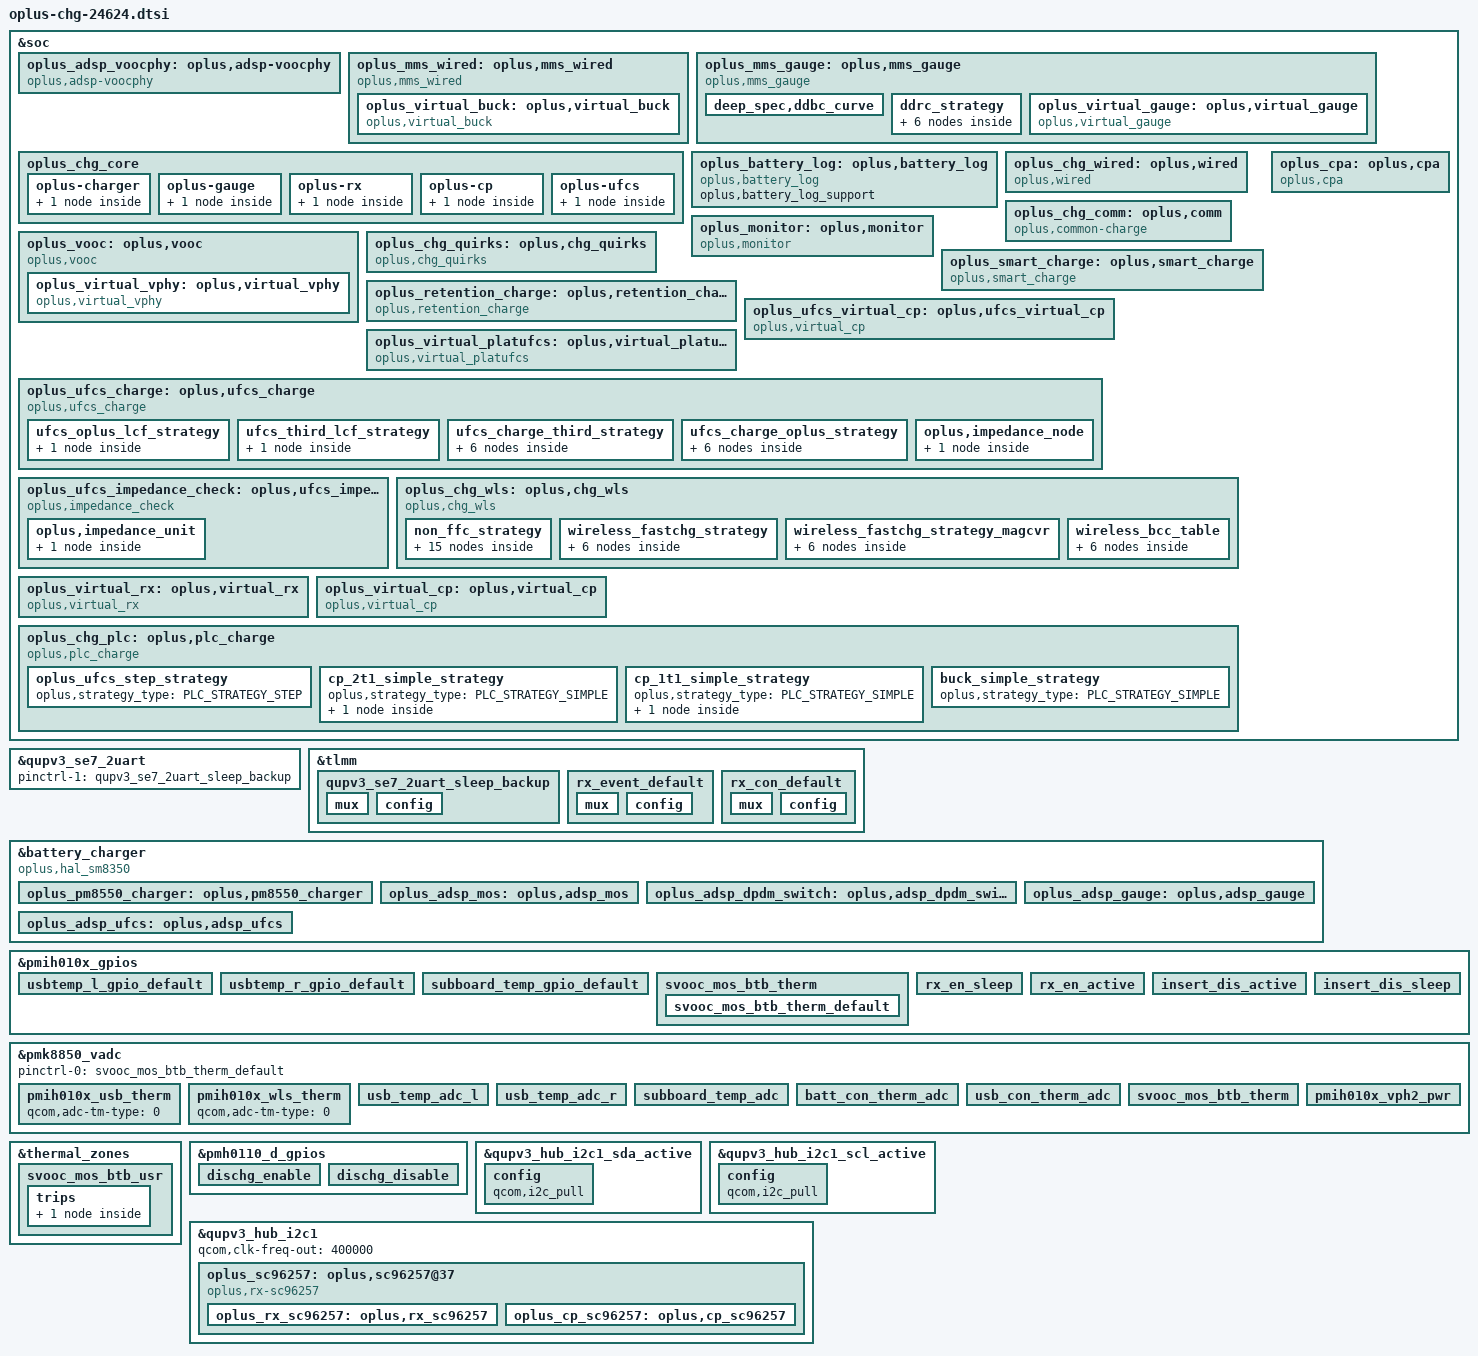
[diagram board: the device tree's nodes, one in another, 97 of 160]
//ifdef OPLUS_FEATURE_CHG_BASIC
//BSP.CHG.Basic, 2023/04/19, sjc Add for charging

#include "oplus-chg-8850.h.dtsi"
#include "oplus-chg-24624-fw.dtsi"

/*
 * NOTICE:
 * sector 1: wired charging
 * sector 2: ufcs
 * sector 3: wls charging
 */

//#ifdef OPLUS_FEATURE_CHG_BASIC /* BSP.CHG.Basic, 2023/04/19, sjc Add for wired charging */
//for wired charging config
&soc {
	oplus_adsp_voocphy: oplus,adsp-voocphy {
		compatible = "oplus,adsp-voocphy";
		oplus,ic_type = <OPLUS_CHG_IC_VPHY>;
		oplus,ic_index = <0>;
		oplus,vooc-version = <VOOC_VERSION_5_0>;

		oplus_spec,vooc_low_temp = <50>;
		oplus_spec,vooc_little_cold_temp = <50>;
		oplus_spec,vooc_cool_temp = <120>;
		oplus_spec,vooc_little_cool_temp = <160>;
		oplus_spec,vooc_little_cool_high_temp = <210>;
		oplus_spec,vooc_normal_low_temp = <350>;
		oplus_spec,vooc_normal_high_temp = <440>;
		oplus_spec,vooc_high_temp = <500>;
		oplus_spec,vooc_over_high_temp = <510>;
		oplus_spec,vooc_low_soc = <0>;
		oplus_spec,vooc_high_soc = <90>;

		oplus_spec,vooc_warm_vol_thr = <4000>;
		oplus_spec,vooc_warm_soc_thr = <55>;
	};

	oplus_mms_wired: oplus,mms_wired {
		compatible = "oplus,mms_wired";
		oplus,buck_ic = <&oplus_virtual_buck>;

		oplus,adc_info_name = "855";

		/* BSP.CHG.Basic, 2024/09/27, Add for:
		High temperature long-term solution for Battery bulge from MTK*/
		high-temp-scheme;

		oplus,support_usbtemp_protect_v2;
		oplus,support_wlsotg_non_coexistence;
		oplus_spec,usbtemp_batt_temp_low = <50>;
		oplus_spec,usbtemp_batt_temp_high = <50>;
		oplus_spec,usbtemp_batt_temp_over_hot = <60>;
		oplus_spec,usbtemp_ntc_temp_low = <57>;
		oplus_spec,usbtemp_ntc_temp_high = <69>;
		oplus_spec,usbtemp_temp_gap_low_with_batt_temp = <7>;
		oplus_spec,usbtemp_temp_gap_with_batt_temp_in_over_hot = <15>;
		oplus_spec,usbtemp_temp_gap_high_with_batt_temp = <12>;
		oplus_spec,usbtemp_temp_gap_low_without_batt_temp = <12>;
		oplus_spec,usbtemp_temp_gap_high_without_batt_temp = <24>;
		oplus_spec,usbtemp_rise_fast_temp_low = <3>;
		oplus_spec,usbtemp_rise_fast_temp_high = <3>;
		oplus_spec,usbtemp_rise_fast_temp_count_low = <30>;
		oplus_spec,usbtemp_rise_fast_temp_count_high = <20>;
		oplus_spec,usbtemp_cool_down_ntc_low = <54>;
		oplus_spec,usbtemp_cool_down_ntc_high = <65>;
		oplus_spec,usbtemp_cool_down_gap_low = <12>;
		oplus_spec,usbtemp_cool_down_gap_high = <20>;
		oplus_spec,usbtemp_cool_down_recover_ntc_low = <48>;
		oplus_spec,usbtemp_cool_down_recover_ntc_high = <60>;
		oplus_spec,usbtemp_cool_down_recover_gap_low = <6>;
		oplus_spec,usbtemp_cool_down_recover_gap_high = <15>;
		oplus_spec,usbtemp_otg_cc_boot_current_limit = <1250>;

		oplus_virtual_buck: oplus,virtual_buck {
			compatible = "oplus,virtual_buck";
			oplus,buck_ic = <&oplus_pm8550_charger>;
			oplus,buck_ic_index = <0>;
			oplus,buck_ic_connect = <OPLUS_CHG_IC_CONNECT_PARALLEL>;
			oplus,main_charger = <0>;
			oplus,buck_ic_current_ratio = <100>;
			oplus,buck_ic_func_group = <&plat_pm8550_groups>;

			oplus,ic_type = <OPLUS_CHG_IC_VIRTUAL_BUCK>;
			oplus,ic_index = <0>;

			oplus,dischg-gpio = <&pmh0110_d_gpios 5 0x00>;
			//oplus,ship-gpio = <&tlmm 76 0x00>;
			oplus,usbtemp_conversion_ratio = <10>;

			pinctrl-names = "usbtemp_l_gpio_default", "usbtemp_r_gpio_default",
						"dischg_enable", "dischg_disable";
			pinctrl-0 = <&usbtemp_l_gpio_default>;
			pinctrl-1 = <&usbtemp_r_gpio_default>;
			pinctrl-2 = <&dischg_enable>;
			pinctrl-3 = <&dischg_disable>;

			io-channels = <&pmk8850_vadc PMIH010X_ADC5_GEN4_AMUX1_GPIO6_100K_PU(1, PMIH010X_SID)>,
					      <&pmk8850_vadc PMIH010X_ADC5_GEN4_AMUX5_GPIO18_100K_PU(1, PMIH010X_SID)>;
			io-channel-names = "usb_temp_adc_l", "usb_temp_adc_r";

			oplus,uart_tx-gpio = <&tlmm 62 0x00>;
			oplus,uart_rx-gpio = <&tlmm 63 0x00>;
		};
	};
	oplus_mms_gauge: oplus,mms_gauge {
		compatible = "oplus,mms_gauge";
		oplus,gauge_ic = <&oplus_virtual_gauge>;
		oplus,topic-update-interval = <5000>;
		oplus,support_subboard_ntc;

		/* three level term volt config for TI28Z729 gauge. */
		oplus_spec,term_volt = <2900 2875 2750>;
		oplus_spec,term_volt_hold_time = <5  5  3>;
		oplus_spec,time_to_drop_per1 = <10 10>;
		/* oplus_spec,recover_term_volt = <2900 2750>; */
		oplus_spec,recover_term_volt_hold_time = <10 10>;

		deep_spec,support;

		deep_spec,uv_thr = <2750>;
		deep_spec,count_thr = <50>;
		deep_spec,vbat_soc = <20>;
		deep_spec,count_step = <0 10 0
					350 12 1
					450 15 2
					530 20 3>;

		deep_spec,term_coeff = <2900 550 0
					3000 600 0
					3050 700 0
					3100 750 0
					3110 750 0
					3150 800 0
					3160 800 0
					3200 900 0
					3210 900 0
					3260 1000 0>;
		deep_spec,ddrc_strategy_name = "ddrc_curve_v2";
		deep_spec,volt_step = <20>;
		deep_spec,ddbc_curve {
			oplus,temp_type = <OPLUS_STRATEGY_USE_BATT_TEMP>;
			oplus,temp_range = <(-100) 0 200>;
			deep_spec,ddbc_temp_cold = <500 3310 5
						   10000 3260 2>;
			deep_spec,ddbc_temp_cool = <500 3310 5
						   10000 3260 2>;
			deep_spec,ddbc_temp_normal = <500 3310 5
						   10000 3260 2>;
			deep_spec,ddbc_temp_warm = <500 3310 5
						   10000 3260 2>;
		};
		ddrc_strategy {
			oplus,temp_type = <OPLUS_STRATEGY_USE_BATT_TEMP>;
			oplus,ratio_range = <20 30 50 70 90>;
			oplus,temp_range = <(-100) 0 100 200 350>;
			strategy_ratio_range_min {
				strategy_temp_0 =	<0 2753 3000 0
							300 2910 3100 1
							700 3010 3150 2
							1100 3061 3160 3
							1500 3111 3210 4
							1900 3161 3260 5>;
				strategy_temp_1 =	<0 2752 3100 0
							400 2910 3100 1
							900 3010 3150 2
							1400 3061 3160 3
							1900 3111 3210 4
							2400 3161 3260 5>;
				strategy_temp_2 =	<0 2752 3100 0
							400 2910 3100 1
							900 3010 3150 2
							1400 3061 3160 3
							1900 3111 3210 4
							2400 3161 3260 5>;
				strategy_temp_3 =	<0 2751 2950 0
							400 2911 3000 1
							900 3000 3010 2
							1400 3060 3110 3
							1900 3111 3160 4
							2400 3160 3210 5>;
				strategy_temp_4 =	<0 2750 2900 0
							400 2900 2910 1
							900 3000 3010 2
							1400 3050 3050 3
							1900 3100 3100 4
							2400 3150 3150 5>;
				strategy_temp_5 =	<0 2750 2900 0
							400 2900 2910 1
							900 3000 3010 2
							1400 3050 3050 3
							1900 3100 3100 4
							2400 3150 3150 5>;
			};
			strategy_ratio_range_low {
				strategy_temp_0 =	<0 2753 3000 0
							250 2910 3100 1
							550 3010 3150 2
							850 3110 3160 3
							1150 3160 3210 4
							1450 3210 3260 5>;
				strategy_temp_1 =	<0 2752 3100 0
							300 2910 3100 1
							700 3010 3150 2
							1100 3061 3160 3
							1500 3111 3210 4
							1900 3161 3260 5>;
				strategy_temp_2 =	<0 2752 3100 0
							300 2910 3100 1
							700 3010 3150 2
							1100 3061 3160 3
							1500 3111 3210 4
							1900 3161 3260 5>;
				strategy_temp_3 =	<0 2751 2950 0
							300 2911 3000 1
							700 3000 3010 2
							1100 3060 3110 3
							1500 3111 3160 4
							1900 3160 3210 5>;
				strategy_temp_4 =	<0 2750 2900 0
							300 2900 2910 1
							700 3000 3010 2
							1100 3050 3050 3
							1500 3100 3100 4
							1900 3150 3150 5>;
				strategy_temp_5 =	<0 2750 2900 0
							300 2900 2910 1
							700 3000 3010 2
							1100 3050 3050 3
							1500 3100 3100 4
							1900 3150 3150 5>;
			};
			strategy_ratio_range_mid_low {
				strategy_temp_0 =	<0 2753 3000 0
							100 2910 3100 1
							250 3010 3150 2
							400 3110 3160 3
							550 3160 3210 4
							700 3210 3260 5>;
				strategy_temp_1 =	<0 2752 3100 0
							100 2910 3100 1
							300 3010 3150 2
							600 3061 3160 3
							900 3111 3210 4
							1200 3161 3260 5>;
				strategy_temp_2 =	<0 2752 3100 0
							100 2910 3100 1
							300 3010 3150 2
							600 3061 3160 3
							900 3111 3210 4
							1200 3161 3260 5>;
				strategy_temp_3 =	<0 2751 2950 0
							100 2911 3000 1
							300 3000 3010 2
							600 3060 3110 3
							900 3111 3160 4
							1200 3160 3210 5>;
				strategy_temp_4 =	<0 2750 2900 0
							100 2900 2910 1
							300 3000 3010 2
							600 3050 3050 3
							900 3100 3100 4
							1200 3150 3150 5>;
				strategy_temp_5 =	<0 2750 2900 0
							100 2900 2910 1
							300 3000 3010 2
							600 3050 3050 3
							900 3100 3100 4
							1200 3150 3150 5>;
			};
			strategy_ratio_range_mid {
				strategy_temp_0 =	<0 2753 3000 0
							50 2910 3100 1
							150 3010 3150 2
							300 3110 3160 3
							450 3160 3210 4
							600 3210 3260 5>;
				strategy_temp_1 =	<0 2752 3100 0
							50 2910 3100 1
							150 3010 3150 2
							350 3061 3160 3
							550 3111 3210 4
							750 3161 3260 5>;
				strategy_temp_2 =	<0 2752 3100 0
							50 2910 3100 1
							150 3010 3150 2
							350 3061 3160 3
							550 3111 3210 4
							750 3161 3260 5>;
				strategy_temp_3 =	<0 2751 2950 0
							50 2911 3000 1
							150 3000 3010 2
							350 3060 3110 3
							550 3111 3160 4
							750 3160 3210 5>;
				strategy_temp_4 =	<0 2750 2900 0
							50 2900 2910 1
							150 3000 3010 2
							350 3050 3050 3
							550 3100 3100 4
							750 3150 3150 5>;
				strategy_temp_5 =	<0 2750 2900 0
							50 2900 2910 1
							150 3000 3010 2
							350 3050 3050 3
							550 3100 3100 4
							750 3150 3150 5>;
			};
			strategy_ratio_range_mid_high {
				strategy_temp_0 =	<0 2753 3000 0
							50 2910 3100 1
							150 3010 3150 2
							250 3110 3160 3
							350 3160 3210 4
							450 3210 3260 5>;
				strategy_temp_1 =	<0 2752 3100 0
							50 2910 3100 1
							150 3010 3150 2
							250 3061 3160 3
							350 3111 3210 4
							450 3161 3260 5>;
				strategy_temp_2 =	<0 2752 3100 0
							50 2910 3100 1
							150 3010 3150 2
							250 3061 3160 3
							350 3111 3210 4
							450 3161 3260 5>;
				strategy_temp_3 =	<0 2751 2950 0
							50 2911 3000 1
							150 3000 3010 2
							250 3060 3110 3
							350 3111 3160 4
							450 3160 3210 5>;
				strategy_temp_4 =	<0 2750 2900 0
							50 2900 2910 1
							150 3000 3010 2
							250 3100 3100 3
							350 3150 3150 4
							450 3200 3200 5>;
				strategy_temp_5 =	<0 2750 2900 0
							50 2900 2910 1
							150 3000 3010 2
							250 3100 3100 3
							350 3150 3150 4
							450 3200 3200 5>;
			};
			strategy_ratio_range_high {
				strategy_temp_0 =	<0 2753 3000 0
							50 2910 3100 1
							150 3010 3150 2
							250 3110 3160 3
							350 3160 3210 4
							450 3210 3260 5>;
				strategy_temp_1 =	<0 2752 3100 0
							50 2910 3100 1
							150 3010 3150 2
							250 3061 3160 3
							350 3111 3210 4
							450 3161 3260 5>;
				strategy_temp_2 =	<0 2752 3100 0
							50 2910 3100 1
							150 3010 3150 2
							250 3061 3160 3
							350 3111 3210 4
							450 3161 3260 5>;
				strategy_temp_3 =	<0 2751 2950 0
							50 2911 3000 1
							150 3000 3010 2
							250 3060 3110 3
							350 3111 3160 4
							450 3160 3210 5>;
				strategy_temp_4 =	<0 2750 2900 0
							50 2900 2910 1
							150 3000 3010 2
							250 3100 3100 3
							350 3150 3150 4
							450 3200 3200 5>;
				strategy_temp_5 =	<0 2750 2900 0
							50 2900 2910 1
							150 3000 3010 2
							250 3100 3100 3
							350 3150 3150 4
							450 3200 3200 5>;
			};
		};
		oplus_virtual_gauge: oplus,virtual_gauge {
			compatible = "oplus,virtual_gauge";
			oplus,gauge_ic = <&oplus_adsp_gauge>;
			oplus,gauge_ic_index = <0>;
			oplus,gauge_ic_func_group = <&adsp_gauge_groups>;
			oplus,batt_capacity_mah = <7000>;
			oplus,ic_type = <OPLUS_CHG_IC_VIRTUAL_GAUGE>;
			oplus,ic_index = <0>;
		};
	};
};

&soc {
	oplus_chg_core {
		oplus,chg_framework_v2;
		oplus,battery_type_by_smem;
		oplus,smart_charging_screenoff;
		oplus,chg_spec_version = <OPLUS_CHG_SPEC_VER_V3P7>;
		oplus,eco_region_list = /bits/ 8 <0x44>;
		oplus,common_chg_region_list = /bits/ 8 <0x44>;
		oplus,common-charge-icl-support;
		oplus,boot_reset_adapter_support;

		oplus-charger {
			plat_pm8550_groups: oplus,plat_pm8550-groups {
				functions = <
					OPLUS_IC_FUNC_INIT
					OPLUS_IC_FUNC_EXIT
					OPLUS_IC_FUNC_REG_DUMP
					OPLUS_IC_FUNC_SMT_TEST
					OPLUS_IC_FUNC_BUCK_INPUT_PRESENT
					OPLUS_IC_FUNC_BUCK_INPUT_SUSPEND
					OPLUS_IC_FUNC_BUCK_INPUT_IS_SUSPEND
					OPLUS_IC_FUNC_BUCK_OUTPUT_SUSPEND
					OPLUS_IC_FUNC_BUCK_OUTPUT_IS_SUSPEND
					OPLUS_IC_FUNC_BUCK_GET_CC_ORIENTATION
					OPLUS_IC_FUNC_BUCK_GET_CHARGER_TYPE
					OPLUS_IC_FUNC_BUCK_RERUN_BC12
					OPLUS_IC_FUNC_BUCK_QC_DETECT_ENABLE
					OPLUS_IC_FUNC_BUCK_SHIPMODE_ENABLE
					OPLUS_IC_FUNC_BUCK_SET_QC_CONFIG
					OPLUS_IC_FUNC_BUCK_SET_PD_CONFIG
					OPLUS_IC_FUNC_GET_SHUTDOWN_SOC
					OPLUS_IC_FUNC_BACKUP_SOC
					OPLUS_IC_FUNC_GET_TYPEC_MODE
					OPLUS_IC_FUNC_BUCK_SET_ICL
					OPLUS_IC_FUNC_BUCK_GET_ICL
					OPLUS_IC_FUNC_BUCK_SET_FCC
					OPLUS_IC_FUNC_BUCK_SET_FV
					OPLUS_IC_FUNC_BUCK_SET_ITERM
					OPLUS_IC_FUNC_BUCK_SET_RECHG_VOL
					OPLUS_IC_FUNC_BUCK_GET_INPUT_CURR
					OPLUS_IC_FUNC_BUCK_GET_INPUT_VOL
					OPLUS_IC_FUNC_GET_CHARGER_CYCLE
					OPLUS_IC_FUNC_OTG_BOOST_ENABLE
					OPLUS_IC_FUNC_SET_OTG_BOOST_CURR_LIMIT
					OPLUS_IC_FUNC_BUCK_GET_VBUS_COLLAPSE_STATUS
					OPLUS_IC_FUNC_GET_OTG_ENABLE
					OPLUS_IC_FUNC_SET_OTG_SWITCH_STATUS
					OPLUS_IC_FUNC_GET_OTG_SWITCH_STATUS
					OPLUS_IC_FUNC_GET_OTG_ONLINE_STATUS
					OPLUS_IC_FUNC_BUCK_GET_HW_DETECT
					OPLUS_IC_FUNC_VOOCPHY_SET_MATCH_TEMP
					OPLUS_IC_FUNC_IS_OPLUS_SVID
					OPLUS_IC_FUNC_BUCK_SET_VINDPM
					OPLUS_IC_FUNC_WLS_BOOST_ENABLE
					OPLUS_IC_FUNC_SET_WLS_BOOST_VOL
					OPLUS_IC_FUNC_SET_WLS_BOOST_CURR_LIMIT
					OPLUS_IC_FUNC_BUCK_WLS_INPUT_SUSPEND
					OPLUS_IC_FUNC_BUCK_SET_WLS_ICL
					OPLUS_IC_FUNC_BUCK_GET_WLS_ICL
					OPLUS_IC_FUNC_BUCK_GET_WLS_INPUT_CURR
					OPLUS_IC_FUNC_BUCK_GET_WLS_INPUT_VOL
					OPLUS_IC_FUNC_BUCK_WLS_AICL_ENABLE
					OPLUS_IC_FUNC_BUCK_WLS_AICL_RERUN
					OPLUS_IC_FUNC_BUCK_DIS_INSERT_DETECT
					OPLUS_IC_FUNC_GET_TYPEC_ROLE
					OPLUS_IC_FUNC_SET_TYPEC_MODE
					OPLUS_IC_FUNC_BUCK_GET_USB_BTB_TEMP
					OPLUS_IC_FUNC_BUCK_GET_BATT_BTB_TEMP
					OPLUS_IC_FUNC_BUCK_GET_TYPEC_STATE
					OPLUS_IC_FUNC_BUCK_GET_USB_AICL_ENHANCE
					OPLUS_IC_FUNC_BUCK_SET_AICL_POINT
					OPLUS_IC_FUNC_BUCK_SET_CHG_PATH
					OPLUS_IC_FUNC_BUCK_GET_CHG_PATH_STATUS
				>;
				virqs = <
					OPLUS_IC_VIRQ_ERR
					OPLUS_IC_VIRQ_CC_DETECT
					OPLUS_IC_VIRQ_PLUGIN
					OPLUS_IC_VIRQ_CC_CHANGED
					OPLUS_IC_VIRQ_SUSPEND_CHECK
					OPLUS_IC_VIRQ_CHG_TYPE_CHANGE
					OPLUS_IC_VIRQ_OTG_ENABLE
					OPLUS_IC_VIRQ_SVID
					OPLUS_IC_VIRQ_TYPEC_STATE
				>;
			};
		};

		oplus-gauge {
			adsp_gauge_groups: oplus,gauge_groups {
				functions = <
					OPLUS_IC_FUNC_INIT
					OPLUS_IC_FUNC_EXIT
					OPLUS_IC_FUNC_REG_DUMP
					OPLUS_IC_FUNC_SMT_TEST
					OPLUS_IC_FUNC_GAUGE_GET_BATT_VOL
					OPLUS_IC_FUNC_GAUGE_GET_BATT_MAX
					OPLUS_IC_FUNC_GAUGE_GET_BATT_MIN
					OPLUS_IC_FUNC_GAUGE_GET_BATT_CURR
					OPLUS_IC_FUNC_GAUGE_GET_BATT_TEMP
					OPLUS_IC_FUNC_GAUGE_GET_BATT_SOC
					OPLUS_IC_FUNC_GAUGE_GET_BATT_FCC
					OPLUS_IC_FUNC_GAUGE_GET_BATT_CC
					OPLUS_IC_FUNC_GAUGE_GET_BATT_RM
					OPLUS_IC_FUNC_GAUGE_GET_BATT_SOH
					OPLUS_IC_FUNC_GAUGE_GET_BATT_AUTH
					OPLUS_IC_FUNC_GAUGE_GET_BATT_HMAC
					/* TODO: remove the battery full to fix the issue of force report full*/
					/*OPLUS_IC_FUNC_GAUGE_SET_BATT_FULL*/
					OPLUS_IC_FUNC_GAUGE_UPDATE_DOD0
					OPLUS_IC_FUNC_GAUGE_UPDATE_SOC_SMOOTH
					OPLUS_IC_FUNC_GAUGE_GET_CB_STATUS
					OPLUS_IC_FUNC_GAUGE_GET_BATT_NUM
					OPLUS_IC_FUNC_GAUGE_GET_DEVICE_TYPE
					OPLUS_IC_FUNC_GAUGE_GET_DEVICE_TYPE_FOR_VOOC
					OPLUS_IC_FUNC_GAUGE_GET_BATT_FCC
					OPLUS_IC_FUNC_GAUGE_UPDATE
					OPLUS_IC_FUNC_GAUGE_IS_SUSPEND
					OPLUS_IC_FUNC_GAUGE_GET_SUBBOARD_TEMP
					OPLUS_IC_FUNC_GAUGE_GET_BCC_PARMS
					OPLUS_IC_FUNC_GAUGE_GET_DEVICE_TYPE_FOR_BCC
					OPLUS_IC_FUNC_GAUGE_GET_DOD0
					OPLUS_IC_FUNC_GAUGE_GET_DOD0_PASSED_Q
					OPLUS_IC_FUNC_GAUGE_GET_QMAX
					OPLUS_IC_FUNC_GAUGE_GET_QMAX_PASSED_Q
					OPLUS_IC_FUNC_GAUGE_GET_REG_INFO
					OPLUS_IC_FUNC_GAUGE_GET_CALIB_TIME
					OPLUS_IC_FUNC_GAUGE_GET_DEEP_DISCHG_COUNT
					OPLUS_IC_FUNC_GAUGE_SET_DEEP_DISCHG_COUNT
					OPLUS_IC_FUNC_GAUGE_SET_DEEP_TERM_VOLT
					OPLUS_IC_FUNC_GAUGE_GET_DEEP_TERM_VOLT
					OPLUS_IC_FUNC_GAUGE_GET_BATT_SN
					OPLUS_IC_FUNC_GAUGE_GET_MANU_DATE
					OPLUS_IC_FUNC_GAUGE_GET_FIRST_USAGE_DATE
					OPLUS_IC_FUNC_GAUGE_SET_FIRST_USAGE_DATE
					OPLUS_IC_FUNC_GAUGE_GET_UI_CC
					OPLUS_IC_FUNC_GAUGE_SET_UI_CC
					OPLUS_IC_FUNC_GAUGE_GET_UI_SOH
					OPLUS_IC_FUNC_GAUGE_SET_UI_SOH
					OPLUS_IC_FUNC_GAUGE_GET_USED_FLAG
					OPLUS_IC_FUNC_GAUGE_SET_USED_FLAG
					OPLUS_IC_FUNC_GAUGE_SET_CALIB_TIME
					OPLUS_IC_FUNC_GAUGE_SET_LAST_CC
					OPLUS_IC_FUNC_GAUGE_GET_LAST_CC
					OPLUS_IC_FUNC_GAUGE_GET_REAL_TIME_CURR
					OPLUS_IC_FUNC_GAUGE_GET_DEC_FG_TYPE
					OPLUS_IC_FUNC_GAUGE_GET_DEC_CV_SOH
					OPLUS_IC_FUNC_GAUGE_SET_VCT
					OPLUS_IC_FUNC_GAUGE_GET_VCT
					OPLUS_IC_FUNC_GAUGE_SET_SILI_IC_ALG_TERM_VOLT
					OPLUS_IC_FUNC_GAUGE_GET_SILI_ALG_APPLICATION_INFO
					OPLUS_IC_FUNC_GAUGE_GET_SILI_LIFETIME_STATUS
					OPLUS_IC_FUNC_GAUGE_GET_SILI_LIFETIME_INFO
					OPLUS_IC_FUNC_GAUGE_GET_GAUGE_CAR_C
					OPLUS_IC_FUNC_GAUGE_SET_CUV_STATE
					OPLUS_IC_FUNC_GAUGE_GET_CUV_STATE
					OPLUS_IC_FUNC_GAUGE_GET_THREE_LEVEL_TERM_VOLT
					OPLUS_IC_FUNC_GAUGE_SET_THREE_LEVEL_TERM_VOLT
					OPLUS_IC_FUNC_GAUGE_SET_TRUE_FCC
				>;
				virqs = <
					OPLUS_IC_VIRQ_ERR
					OPLUS_IC_VIRQ_OFFLINE
					OPLUS_IC_VIRQ_RESUME
					OPLUS_IC_VIRQ_HMAC_UPDATE
				>;
			};
		};

		oplus-rx {
			sc96257_rx_groups: oplus,rx_groups {
				functions = <
					OPLUS_IC_FUNC_INIT
					OPLUS_IC_FUNC_EXIT
					OPLUS_IC_FUNC_REG_DUMP
					OPLUS_IC_FUNC_SMT_TEST
					OPLUS_IC_FUNC_RX_SET_ENABLE
					OPLUS_IC_FUNC_RX_IS_ENABLE
					OPLUS_IC_FUNC_RX_IS_CONNECTED
					OPLUS_IC_FUNC_RX_GET_VOUT
					OPLUS_IC_FUNC_RX_SET_VOUT
					OPLUS_IC_FUNC_RX_GET_VRECT
					OPLUS_IC_FUNC_RX_GET_IOUT
					OPLUS_IC_FUNC_RX_GET_TRX_VOL
					OPLUS_IC_FUNC_RX_GET_TRX_CURR
					OPLUS_IC_FUNC_RX_GET_CEP_COUNT
					OPLUS_IC_FUNC_RX_GET_CEP_VAL
					OPLUS_IC_FUNC_RX_GET_WORK_FREQ
					OPLUS_IC_FUNC_RX_GET_RX_MODE
					OPLUS_IC_FUNC_RX_SET_RX_MODE
					OPLUS_IC_FUNC_RX_SET_DCDC_ENABLE
					OPLUS_IC_FUNC_RX_SET_TRX_ENABLE
					OPLUS_IC_FUNC_RX_SET_TRX_START
					OPLUS_IC_FUNC_RX_GET_TRX_STATUS
					OPLUS_IC_FUNC_RX_GET_TRX_ERR
					OPLUS_IC_FUNC_RX_GET_HEADROOM
					OPLUS_IC_FUNC_RX_SET_HEADROOM
					OPLUS_IC_FUNC_RX_SEND_MATCH_Q
					OPLUS_IC_FUNC_RX_SET_FOD_PARM
					OPLUS_IC_FUNC_RX_SEND_MSG
					OPLUS_IC_FUNC_RX_REG_MSG_CALLBACK
					OPLUS_IC_FUNC_RX_GET_RX_VERSION
					OPLUS_IC_FUNC_RX_GET_TRX_VERSION
					OPLUS_IC_FUNC_RX_UPGRADE_FW_BY_BUF
					OPLUS_IC_FUNC_RX_UPGRADE_FW_BY_IMG
					OPLUS_IC_FUNC_RX_CHECK_CONNECT
					OPLUS_IC_FUNC_RX_GET_EVENT_CODE
					OPLUS_IC_FUNC_RX_GET_BRIDGE_MODE
					OPLUS_IC_FUNC_RX_DIS_INSERT
					OPLUS_IC_FUNC_RX_STANDBY_CONFIG
					OPLUS_IC_FUNC_RX_SET_COMU
					OPLUS_IC_FUNC_RX_GET_TX_ID
					OPLUS_IC_FUNC_RX_SET_SILENT
				>;
				virqs = <
					OPLUS_IC_VIRQ_ERR
					OPLUS_IC_VIRQ_PRESENT
					OPLUS_IC_VIRQ_ONLINE
					OPLUS_IC_VIRQ_OFFLINE
					OPLUS_IC_VIRQ_EVENT_CHANGED
				>;
			};
		};

		oplus-cp {
			sc96257_cp_groups: oplus,cp_groups {
				functions = <
					OPLUS_IC_FUNC_INIT
					OPLUS_IC_FUNC_EXIT
					OPLUS_IC_FUNC_REG_DUMP
					OPLUS_IC_FUNC_SMT_TEST
					OPLUS_IC_FUNC_CP_ENABLE
					OPLUS_IC_FUNC_CP_SET_WORK_START
				>;
				virqs = <
					OPLUS_IC_VIRQ_ERR
					OPLUS_IC_VIRQ_ONLINE
					OPLUS_IC_VIRQ_OFFLINE
				>;
			};
		};

		oplus-ufcs {
			adsp_ufcs_groups: oplus,ufcs_groups {
				functions = <
					OPLUS_IC_FUNC_INIT
					OPLUS_IC_FUNC_EXIT
					OPLUS_IC_FUNC_REG_DUMP
					OPLUS_IC_FUNC_SMT_TEST
					OPLUS_IC_FUNC_UFCS_HANDSHAKE
					OPLUS_IC_FUNC_UFCS_PDO_SET
					OPLUS_IC_FUNC_UFCS_HARD_RESET
					OPLUS_IC_FUNC_UFCS_EXIT
					OPLUS_IC_FUNC_UFCS_CONFIG_WD
					OPLUS_IC_FUNC_UFCS_GET_DEV_INFO
					OPLUS_IC_FUNC_UFCS_GET_ERR_INFO
					OPLUS_IC_FUNC_UFCS_GET_SRC_INFO
					OPLUS_IC_FUNC_UFCS_GET_CABLE_INFO
					OPLUS_IC_FUNC_UFCS_GET_PDO_INFO
					OPLUS_IC_FUNC_UFCS_VERIFY_ADAPTER
					OPLUS_IC_FUNC_UFCS_GET_POWER_CHANGE_INFO
					OPLUS_IC_FUNC_UFCS_GET_EMARK_INFO
					OPLUS_IC_FUNC_UFCS_GET_POWER_INFO_EXT
					OPLUS_IC_FUNC_UFCS_IS_TEST_MODE
					OPLUS_IC_FUNC_UFCS_SET_SM_PERIOD
				>;
				virqs = <
					OPLUS_IC_VIRQ_ERR
					OPLUS_IC_VIRQ_ONLINE
					OPLUS_IC_VIRQ_OFFLINE
				>;
			};
		};
	};
};

&qupv3_se7_2uart {
	pinctrl-1 = <&qupv3_se7_2uart_sleep_backup>;
	status = "okay";
};

&tlmm {
	qupv3_se7_2uart_sleep_backup:qupv3_se7_2uart_sleep_backup {
		mux {
			pins = "gpio62", "gpio63";
			function = "gpio";
		};

		config {
			pins = "gpio62", "gpio63";
			drive-strength = <2>;
			bias-disable;
			input-enable;
		};
	};
};

&battery_charger {
	//for oplus chg framework:
	oplus,chg_ops = "plat-pmic";
	//qcom,pmic_ftm_vph = "/sys/bus/spmi/drivers/pmic-spmi/0-00/c426000.spmi:pmk8850@0:vadc@9000/iio:device0/in_voltage_pmih010x_vph2_pwr_input";
	//qcom,pmic_ftm_vbat = "/sys/bus/spmi/drivers/pmic-spmi/0-00/c426000.spmi:pmk8850@0:vadc@9000/iio:device0/in_voltage_pmih010x_vbat_sns_qbg_input";
	oplus,usb_aicl_enhance;

	/*qcom,otg-booster-en-gpio = <&pm8550ve_i_gpios 8 0x00>;
	qcom,otg-ovp-en-gpio = <&pmih010x_gpios 11 0x00>;
	oplus,wrx_otg_en-gpio = <&pm8550_gpios 1 0x00>;//wls nor OVP check
	pinctrl-names = "otg_booster_en_active", "otg_booster_en_sleep",
			"otg_ovp_en_active", "otg_ovp_en_sleep",
			"subboard_temp_gpio_default";
	pinctrl-0 = <&otg_booster_en_active>;
	pinctrl-1 = <&otg_booster_en_sleep>;
	pinctrl-2 = <&otg_ovp_en_active>;
	pinctrl-3 = <&otg_ovp_en_sleep>;
	pinctrl-4 = <&subboard_temp_gpio_default>;*/
	//pinctrl-5 = <&wrx_otg_en_active>;
	//pinctrl-6 = <&wrx_otg_en_sleep>;

};

&battery_charger {
	compatible = "oplus,hal_sm8350";
	oplus,vphy_ic = <&oplus_adsp_voocphy>;
	oplus,voocphy_support;
	oplus,vooc_project = <14>;
	oplus,batt_num = <2>;
	oplus,otg_scheme = <0>;//0:cid 1:ccdetect_gpio 2:switch
	oplus,ufcs_run_check_support;
	oplus,soccp_support;

	oplus_pm8550_charger: oplus,pm8550_charger {
		oplus,ic_type = <OPLUS_CHG_IC_BUCK>;
		oplus,ic_index = <0>;
	};
	oplus_adsp_mos: oplus,adsp_mos {
		oplus,ic_type = <OPLUS_CHG_IC_CP>;
		oplus,ic_index = <0>;
	};
	oplus_adsp_dpdm_switch: oplus,adsp_dpdm_switch {
		oplus,ic_type = <OPLUS_CHG_IC_MISC>;
		oplus,ic_index = <0>;
	};
	oplus_adsp_gauge: oplus,adsp_gauge {
		oplus,ic_type = <OPLUS_CHG_IC_GAUGE>;
		oplus,ic_index = <0>;
		oplus,ic_devinfo = "sn28z729","TI";
	};
	oplus_adsp_ufcs: oplus,adsp_ufcs {
		oplus,ic_type = <OPLUS_CHG_IC_UFCS>;
		oplus,ic_index = <0>;
	};
};

&soc {
	oplus_battery_log: oplus,battery_log {
		compatible = "oplus,battery_log";

		oplus,battery_log_support;
	};

	oplus_chg_wired: oplus,wired {
		compatible = "oplus,wired";

		oplus,vooc-support;
		oplus,pdqc12v-support;

		oplus_spec,vbatt_pdqc_to_5v_thr = <5100>;
		oplus_spec,vbatt_pdqc_to_9v_thr = <5000>;
		oplus_spec,pd-iclmax-ma = <3000>;
		oplus_spec,qc-iclmax-ma = <3000>;
		oplus_spec,non-standard-ibatmax-ma = <500>;
		oplus_spec,input-power-mw = <
			2500		/* OPLUS_WIRED_CHG_MODE_UNKNOWN */
			2500		/* OPLUS_WIRED_CHG_MODE_SDP */
			7500		/* OPLUS_WIRED_CHG_MODE_CDP */
			10000		/* OPLUS_WIRED_CHG_MODE_DCP */
			15000		/* OPLUS_WIRED_CHG_MODE_VOOC */
			18000		/* OPLUS_WIRED_CHG_MODE_QC */
			18000		/* OPLUS_WIRED_CHG_MODE_PD */
			36000		/* OPLUS_WIRED_CHG_MODE_QC12V */
			36000		/* OPLUS_WIRED_CHG_MODE_PD12V */
		>;
		oplus_spec,led_on-fccmax-ma = <0 158 317 953 1589 3178 4400 500 0>;
		oplus_spec,fccmax-ma-lv = <
			0 158  317  953 1100 1100 1100 1100 0	/* OPLUS_WIRED_CHG_MODE_UNKNOWN */
			0 158  300  300  300  300  300  300 0	/* OPLUS_WIRED_CHG_MODE_SDP */
			0 158  317  800  800  800  800  800 0	/* OPLUS_WIRED_CHG_MODE_CDP */
			0 158  317  953 1100 1100 1100 1100 0	/* OPLUS_WIRED_CHG_MODE_DCP */
			0 158  317  953 1589 1650 1650 1650 0	/* OPLUS_WIRED_CHG_MODE_VOOC */
			0 158  317  953 1589 2200 2200 1840 0	/* OPLUS_WIRED_CHG_MODE_QC */
			0 158  317  953 1589 2200 2200 1840 0	/* OPLUS_WIRED_CHG_MODE_PD */
			0 158  317  953 1589 3178 4400 1840 0	/* OPLUS_WIRED_CHG_MODE_QC12v */
			0 158  317  953 1589 3178 4400 1840 0	/* OPLUS_WIRED_CHG_MODE_PD12v */
		>;
		oplus_spec,fccmax-ma-hv = <
			0 158  317  635  953 1589 1650 1650 0	/* OPLUS_WIRED_CHG_MODE_UNKNOWN */
			0 158  300  300  300  300  300  300 0	/* OPLUS_WIRED_CHG_MODE_SDP */
			0 158  317  635  800  800  800  800 0	/* OPLUS_WIRED_CHG_MODE_CDP */
			0 158  317  635  953 1100 1100 1100 0	/* OPLUS_WIRED_CHG_MODE_DCP */
			0 158  317  635  953 1589 1650 1650 0	/* OPLUS_WIRED_CHG_MODE_VOOC */
			0 158  317  635  953 1589 2200 1840 0	/* OPLUS_WIRED_CHG_MODE_QC */
			0 158  317  635  953 1589 2200 1840 0	/* OPLUS_WIRED_CHG_MODE_PD */
			0 158  317  635  935 1589 4400 1840 0	/* OPLUS_WIRED_CHG_MODE_QC12V */
			0 158  317  635  935 1589 4400 1840 0	/* OPLUS_WIRED_CHG_MODE_PD12V */
		>;

		oplus_spec,cool_down_sale_pdqc_vol_mv = <9000>;
		oplus_spec,cool_down_sale_pdqc_curr_ma = <1200>;
		oplus_spec,cool_down_pdqc_vol_mv = <9000 9000 9000 9000 9000>;
		oplus_spec,cool_down_pdqc_curr_ma = <1200 1500 2000 2500 3000>;
		oplus_spec,cool_down_vooc_curr_ma = <1200 1500 2000 2500 3000 3000>;
		oplus_spec,cool_down_normal_curr_ma = <1200 1500 2000>;

		oplus_spec,vbus_ov_thr_mv = <13000 13000 13000>;
		oplus_spec,vbus_uv_thr_mv = <4300 4300 4300>;

		/* first data is strategy used temp type */
		oplus,vooc_strategy_name = "cgcl";
		oplus,vooc_strategy_data = <OPLUS_STRATEGY_USE_BATT_TEMP
					    0   350 3600 1 0
					    330 370 3200 2 0
					    350 440 2200 2 1>;
	};

	oplus_chg_comm: oplus,comm {
		compatible = "oplus,common-charge";
		oplus_spec,dec_step = <20>;
		oplus_spec,dec-vol-cc-full-thr = <0 200 400 600 800 1000>;
		oplus_spec,dec-vol-fv-full-mv = <0 20 40 40 60 60>;
		oplus_spec,dec-vol-vct-mv = <100 120 140 140 160 160>;
		oplus_spec,batt-them-thr = <(-100) 0 50 120 160 350 450 530>;
		oplus_spec,iterm-ma = <158>;
		oplus_spec,fv-mv = <4520 4520 4530 4530 4530 4530 4500 4130 4130>;
		oplus_spec,sw-fv-mv = <4470 4470 4480 4480 4480 4480 4450 4080 4080>;
		oplus_spec,hw-fv-inc-mv = <0 18 18 18 18 18 18 18 0>;
		oplus_spec,sw-over-fv-mv = <4530 4530 4540 4540 4540 4540 4510 4140 4140>;
		oplus_spec,sw-over-fv-dec-mv = <8>;
		oplus_spec,non-standard-sw-fv-mv = <3930>;
		oplus_spec,non-standard-fv-mv = <3980>;
		oplus_spec,non-standard-hw-fv-inc-mv = <18>;
		oplus_spec,non-standard-sw-over-fv-mv = <3990>;
		oplus_spec,non-standard-vbatdet-mv = <3680>;
		oplus_spec,wired-vbatdet-mv = <0 4220 4430 4430 4430 4430 4400 4030 0>;
		oplus_spec,wls-vbatdet-mv = <0 4220 4430 4430 4430 4430 4400 4030 0>;
		oplus_spec,fcc-gear-thr-mv = <4180>;
		oplus_spec,fcc-gear-shake-mv = <400 400 400 300 300 180 180 180 180>;
		oplus_spec,vbatt-ov-thr-mv = <4600>;
		oplus_spec,full_pre_ffc_judge;
		oplus_spec,full-pre-ffc-mv = <4525>;
		oplus_spec,ffc-temp-thr = <120 210 350 440>;
		oplus_spec,wired-ffc-step-max = <2>;
		oplus_spec,wired-ffc-fv-mv = <4610 4610>;

		oplus_spec,wired-ffc-fv-cutoff-mv = <4560 4545 4515
						     4540 4530 4500>;

		oplus_spec,removed_bat_decidegc = <390>;

		oplus_spec,wired-ffc-fcc-ma = <550 550 550
					       350  350  350>;
		oplus_spec,wired-ffc-fcc-cutoff-ma = <400 400 400
						      200 200 200>;

		oplus_spec,drop_soc_2_temp_ladder = <(-50) 0 0 0 0 0 0 0 0 0>;
		oplus_spec,volt_diff_ladder_of_drop_soc_2 = <80 80 0 0 0 0 0 0 0 0>;
		oplus_spec,keep_soc_2_temp_ladder = <(-200) (-50) 0 0 0 0 0 0 0 0>;
		oplus_spec,volt_diff_ladder_of_keep_soc_2 = <10 20 30 0 0 0 0 0 0 0>;
		oplus_spec,back_rm_of_drop_soc_2 = <36>;
		oplus_spec,back_rm_of_drop_soc_1 = <0>;
		oplus_spec,load_current_of_drop_soc_2 = <1500>;
		oplus_spec,load_current_of_drop_soc_1 = <2000>;
		oplus_spec,current_limit_of_drop_soc_2 = <350>;
		oplus_spec,volt_of_fast_drop_soc_1 = <2750>;
		oplus_spec,support_uisoc_low_battery_control;

		oplus_spec,wls-ffc-step-max = <2>;
		oplus_spec,wls-ffc-fv-mv = <4610 4610>;
		oplus_spec,wls-ffc-fv-cutoff-mv = <4560 4545 4515
						   4540 4530 4500>;
		oplus_spec,wls-ffc-icl-ma = <850 850 850
					     550 550 550>;
		oplus_spec,wls-ffc-fcc-ma = <550 550 550
					     350 350 350>;
		oplus_spec,wls-ffc-fcc-cutoff-ma = <400 400 400
						    200 200 200>;
		oplus_spec,vbat_uv_thr_mv = <2750>;
		oplus_spec,vbat_charging_uv_thr_mv = <2650>;

		/*If use subboard NTC as battery temp, config it as 20, otherwise 0 */
		oplus_spec,tbatt_power_off_cali_temp = <0>;
		oplus,vooc_show_ui_soc_decimal;
		oplus_spec,poweroff_high_batt_temp = <720>;
		oplus_spec,poweroff_emergency_batt_temp = <770>;
		oplus,ui_soc_decimal_speedmin = <20>;

		oplus,gauge_stuck_jump_support;
		oplus,gauge_stuck_threshold = <15>;
		oplus,gauge_stuck_time = <50>;

		oplus_spec,sw_check_full_cnt = <12>;

		oplus,hidden_soc_switch;
		oplus,reserve_chg_soc = <2>;
		oplus,hidden_soc_percent = <20>;

		oplus,ui_soc_2_voltage_comp_mv = <30>;
		oplus,chg_shutdown_max_mv = <2750>;
		oplus,eco_region_list = /bits/ 8 <0x44>;
	};

	oplus_monitor: oplus,monitor {
		compatible = "oplus,monitor";
		oplus,topic-update-interval = <60000>;

		track,fast_chg_break_t_thd = <2500>;
		track,general_chg_break_t_thd = <300>;
		track,voocphy_type = <1>;
		track,wired_max_power = <100000>;
		track,wired_fast_chg_scheme = <0>;

		track,wls_max_power = <50000>;
		track,wls_bpp_chg_scheme = <0>;
		track,wls_epp_chg_scheme = <0>;
		track,wls_fast_chg_scheme = <0>;

		track,gauge_status_ctrl;
		track,external_gauge_num = <1>;

		track,gauge_max_cell_vol = <4600>;
		track,gauge_max_charge_curr = <13000>;
		track,gauge_max_dischg_curr = <6000>;
		track,gauge_min_cell_temp = <30>;
		track,gauge_max_cell_temp = <70>;
		track,gauge_lifetime_support;
		track,nominal_qmax1 = <3707>;
		track,nominal_fcc1 = <6440>;
		track,low_soc_monitor_ctrl;
		track,track_ver = <TRACK_VER_4_0>;
	};

	oplus_vooc: oplus,vooc {
		compatible = "oplus,vooc";
		oplus,vooc_ic = <&oplus_virtual_vphy>;

		oplus_spec,silicon_vooc_soc_range = <20 35 55 75 85>;

		oplus,vooc_data_width = <7>;
		oplus,vooc_curr_max = <CURR_LIMIT_7BIT_11_0A>;
		oplus,support_vooc_by_normal_charger_path;
		oplus,vooc_project = <14>;
		oplus,vooc_curr_table_type = <VOOC_CURR_TABLE_2_0>;
		oplus,vooc_power_max_w = <120>;
		oplus,voocphy_support = <1>;
		oplus,support_fake_vooc_check;
		oplus,subboard_ntc_abnormal_current = <7300>;
		oplus,smart_chg_bcc_support;
		oplus,abnormal_over_80w_adapter_current = <CURR_LIMIT_7BIT_11_5A CURR_LIMIT_7BIT_11_5A
						CURR_LIMIT_7BIT_7_0A CURR_LIMIT_7BIT_7_0A
						CURR_LIMIT_7BIT_6_0A CURR_LIMIT_7BIT_6_0A
						CURR_LIMIT_7BIT_5_0A CURR_LIMIT_7BIT_5_0A
						CURR_LIMIT_7BIT_4_0A CURR_LIMIT_7BIT_4_0A
						CURR_LIMIT_7BIT_3_0A CURR_LIMIT_7BIT_3_0A
						CURR_LIMIT_7BIT_2_0A CURR_LIMIT_7BIT_2_0A>;


		oplus,abnormal_adapter_current = <CURR_LIMIT_7BIT_11_5A CURR_LIMIT_7BIT_11_5A
						CURR_LIMIT_7BIT_5_0A CURR_LIMIT_7BIT_5_0A
						CURR_LIMIT_7BIT_4_0A CURR_LIMIT_7BIT_4_0A
						CURR_LIMIT_7BIT_3_0A CURR_LIMIT_7BIT_3_0A
						CURR_LIMIT_7BIT_2_0A CURR_LIMIT_7BIT_2_0A>;

		/* first data is strategy used temp type */
		oplus,general_strategy_name = "cgcl";
		oplus,general_strategy_data = < OPLUS_STRATEGY_USE_SHELL_TEMP
						0   420 CURR_LIMIT_7BIT_11_5A 1 0
						395 430 CURR_LIMIT_7BIT_5_5A 2 0
						420 435 CURR_LIMIT_7BIT_3_5A 3 1
						430 440 CURR_LIMIT_7BIT_2_0A 3 2 >;

		oplus,plc_strategy-data = <&buck_simple_strategy &cp_2t1_simple_strategy &cp_1t1_simple_strategy>;
		oplus,plc_strategy-names = "default", "svooc", "vooc";

		oplus_virtual_vphy: oplus,virtual_vphy {
			compatible = "oplus,virtual_vphy";
			oplus,vphy_ic = <&oplus_adsp_voocphy>;

			oplus,ic_type = <OPLUS_CHG_IC_VIRTUAL_VPHY>;
			oplus,ic_index = <0>;
		};
	};
	oplus_smart_charge: oplus,smart_charge {
		compatible = "oplus,smart_charge";
		oplus,quick_mode_gain_support;
		oplus,smart_chg_soh_support;
	};
	oplus_chg_quirks: oplus,chg_quirks {
		compatible = "oplus,chg_quirks";
	};
	oplus_retention_charge: oplus,retention_charge {
		compatible = "oplus,retention_charge";
		oplus,support_retention_name = "oplus_retention_quirks";
	};
};

&pmih010x_gpios {
	usbtemp_l_gpio_default: usbtemp_l_gpio_default {
		pins = "gpio6"; //GPIO 6
		function = "normal"; //normal
		bias-high-impedance; //DISABLE GPIO5 for ADC
		bias-disable;
	};
	usbtemp_r_gpio_default: usbtemp_r_gpio_default {
		pins = "gpio18"; //GPIO 18
		function = "normal"; //normal
		bias-high-impedance; //DISABLE GPIO10 for ADC
		bias-disable;
	};
	subboard_temp_gpio_default: subboard_temp_gpio_default {
		pins = "gpio12"; //GPIO 12
		function = "normal"; //normal
		bias-high-impedance; //DISABLE GPIO6 for ADC
		bias-disable;
	};
	svooc_mos_btb_therm {
		svooc_mos_btb_therm_default: svooc_mos_btb_therm_default {
			pins = "gpio15";
			function = "normal"; //normal
			bias-high-impedance;
			bias-disable;
		};
	};

};

&pmk8850_vadc {
	pinctrl-0 = <&svooc_mos_btb_therm_default>;
	pinctrl-names = "default";

	pmih010x_usb_therm { //for PMIH010X_ADC5_GEN4_AMUX_THM4_USB_THERM_100K_PU
		qcom,adc-tm-type = <0>;
	};

	pmih010x_wls_therm  { //for PMIH010X_ADC5_GEN4_AMUX4_GPIO12_100K_PU
		qcom,adc-tm-type = <0>;
	};

	usb_temp_adc_l {
		reg = <PMIH010X_ADC5_GEN4_AMUX1_GPIO6_100K_PU(1, PMIH010X_SID)>;
		label = "usb_temp_adc_l";
		qcom,pre-scaling = <1 1>;
		qcom,hw-settle-time = <200>;
		qcom,adc5-gen4;
		qcom,scale-fn-type = <OPLUS_ADC_SCALE_HW_CALIB_DEFAULT>;
	};
	usb_temp_adc_r {
		reg = <PMIH010X_ADC5_GEN4_AMUX5_GPIO18_100K_PU(1, PMIH010X_SID)>;
		label = "usb_temp_adc_r";
		qcom,pre-scaling = <1 1>;
		qcom,hw-settle-time = <200>;
		qcom,adc5-gen4;
		qcom,scale-fn-type = <OPLUS_ADC_SCALE_HW_CALIB_DEFAULT>;
	};

	subboard_temp_adc {
		reg = <PMIH010X_ADC5_GEN4_AMUX4_GPIO12_100K_PU(1, PMIH010X_SID)>;
		label = "subboard_temp_adc";
		qcom,pre-scaling = <1 1>;
		qcom,ratiometric;
		qcom,hw-settle-time = <200>;
		qcom,adc5-gen4;
	};
	batt_con_therm_adc {
		reg = <PMIH010X_ADC5_GEN4_AMUX_THM1_BAT_THERM_100K_PU(1, PMIH010X_SID)>;
		label = "batt_con_therm_adc";
		qcom,ratiometric;
		qcom,hw-settle-time = <200>;
		qcom,pre-scaling = <1 1>;
		qcom,adc-tm-type = <0>;
		qcom,adc5-gen4;
	};
	usb_con_therm_adc {
		reg = <PMIH010X_ADC5_GEN4_AMUX_THM4_USB_THERM_100K_PU(1, PMIH010X_SID)>;
		label = "usb_con_therm_adc";
		qcom,ratiometric;
		qcom,hw-settle-time = <200>;
		qcom,pre-scaling = <1 1>;
		qcom,adc-tm-type = <0>;
		qcom,adc5-gen4;
	};

	svooc_mos_btb_therm {
		reg = <PMIH010X_ADC5_GEN4_AMUX2_BAT2_ID_100K_PU(1, PMIH010X_SID)>;
		label = "svooc_mos_btb_therm";
		qcom,ratiometric;
		qcom,hw-settle-time = <200>;
		qcom,pre-scaling = <1 1>;
		qcom,adc-tm-type = <1>;
		qcom,adc5-gen4;
	};

	pmih010x_vph2_pwr {
		reg = <PMIH010X_ADC5_GEN4_VPH2_PWR(1, PMIH010X_SID)>;
		label = "pmih010x_vph2_pwr";
		qcom,pre-scaling = <1 3>;
		qcom,adc5-gen4;
	};
};

&thermal_zones {
	svooc_mos_btb_usr {
		polling-delay-passive = <0>;
		polling-delay = <0>;
		thermal-sensors = <&pmk8850_vadc PMIH010X_ADC5_GEN4_AMUX2_BAT2_ID_100K_PU(1, PMIH010X_SID)>;
		trips {
			active-config0 {
				temperature = <125000>;
				hysteresis = <1000>;
				type = "passive";
			};
		};
	};
};

&battery_charger {
	io-channels	= <&pmk8850_vadc PMIH010X_ADC5_GEN4_AMUX1_GPIO6_100K_PU(1, PMIH010X_SID)>,
					<&pmk8850_vadc PMIH010X_ADC5_GEN4_AMUX5_GPIO18_100K_PU(1, PMIH010X_SID)>,
					<&pmk8850_vadc PMIH010X_ADC5_GEN4_AMUX4_GPIO12_100K_PU(1, PMIH010X_SID)>,
					<&pmk8850_vadc PMIH010X_ADC5_GEN4_AMUX_THM1_BAT_THERM_100K_PU(1, PMIH010X_SID)>,
					<&pmk8850_vadc PMIH010X_ADC5_GEN4_AMUX_THM4_USB_THERM_100K_PU(1, PMIH010X_SID)>,
					<&pmk8850_vadc PMIH010X_ADC5_GEN4_AMUX2_BAT2_ID_100K_PU(1, PMIH010X_SID)>,
					<&pmk8850_vadc PMIH010X_ADC5_GEN4_VPH2_PWR(1, PMIH010X_SID)>,
					<&pmk8850_vadc PMIH010X_ADC5_GEN4_VBAT_SNS_QBG(1, PMIH010X_SID)>;
	io-channel-names = "usb_temp_adc_l", "usb_temp_adc_r", "subboard_temp_adc",
				       "batt_con_therm_adc", "usb_con_therm_adc", "svooc_mos_btb_therm",
				       "vph_pwr", "vbat_sns_qbg";
};

&pmh0110_d_gpios {
	dischg_enable: dischg_enable {
		pins = "gpio5";
		function = "normal";
		bias-disable;
		power-source = <0>;
		output-high;
		qcom,drive-strength = <3>;
	};
	dischg_disable: dischg_disable {
		pins = "gpio5";
		function = "normal";
		bias-disable;
		power-source = <0>;
		output-low;
		qcom,drive-strength = <3>;
	};
};
/*
&pm8550ve_i_gpios {
	otg_booster_en_active: otg_booster_en_active {
		pins = "gpio8";
		function = "normal";
		bias-disable;
		power-source = <0>;
		output-high;
		qcom,drive-strength = <3>;
	};
	otg_booster_en_sleep: otg_booster_en_sleep {
		pins = "gpio8";
		function = "normal";
		bias-disable;
		power-source = <0>;
		output-low;
		qcom,drive-strength = <3>;
	};
};

&pmih010x_gpios {
	otg_ovp_en_active: otg_ovp_en_active {
		pins = "gpio11";
		function = "normal";
		bias-disable;
		power-source = <0>;
		output-high;
		qcom,drive-strength = <3>;
	};
	otg_ovp_en_sleep: otg_ovp_en_sleep {
		pins = "gpio11";
		function = "normal";
		bias-disable;
		power-source = <0>;
		output-low;
		qcom,drive-strength = <3>;
	};
};*/

//#endif OPLUS_FEATURE_CHG_BASIC /*for wired charging config*/

//#ifdef OPLUS_FEATURE_CHG_BASIC /*for ufcs config*/
&soc {
	oplus_cpa: oplus,cpa {
		compatible = "oplus,cpa";
		/* format: <protocol_type power_w> */
		oplus,protocol_list = <CHG_PROTOCOL_UFCS  120
					   CHG_PROTOCOL_VOOC 120
					   CHG_PROTOCOL_PPS  55
					   CHG_PROTOCOL_PD   36
					   CHG_PROTOCOL_QC   36>;
		oplus,default_protocol_list = <CHG_PROTOCOL_UFCS
						   CHG_PROTOCOL_PD
						   CHG_PROTOCOL_VOOC
						   CHG_PROTOCOL_PPS>;
	};

	oplus_ufcs_virtual_cp: oplus,ufcs_virtual_cp {
		compatible = "oplus,virtual_cp";

		oplus,ic_type = <OPLUS_CHG_IC_VIRTUAL_CP>;
		oplus,ic_index = <1>;

		oplus,cp_ic = <&oplus_adsp_mos>;
		oplus,input_curr_max_ma = <12300>;

		oplus,cp_ic_connect = <OPLUS_CHG_IC_CONNECT_PARALLEL>;
		oplus,main_cp = <0>;
	};

	oplus_virtual_platufcs: oplus,virtual_platufcs {
		compatible = "oplus,virtual_platufcs";

		oplus,ufcs_ic = <&oplus_adsp_ufcs>;
		oplus,ufcs_ic_index = <0>;
		oplus,ufcs_ic_connect = <OPLUS_CHG_IC_CONNECT_PARALLEL>;

		oplus,ufcs_ic_func_group = <&adsp_ufcs_groups>;
		oplus,ic_type = <OPLUS_CHG_IC_VIRTUAL_UFCS>;
		oplus,ic_index = <0>;
	};

	oplus_ufcs_charge: oplus,ufcs_charge {
		compatible = "oplus,ufcs_charge";
		oplus,ufcs_ic = <&oplus_virtual_platufcs>;
		oplus,cp_ic = <&oplus_ufcs_virtual_cp>;
		oplus,dpdm_switch_ic = <&oplus_adsp_dpdm_switch>;

		oplus,adsp_ufcs_project;
		oplus,impedance_unit = <&oplus_ufcs_impedance_unit>;
		oplus,ufcs_need_reset_adapter;

		oplus,target_vbus_mv = <11000>;
		oplus,curr_max_ma = <10900>;
		oplus,curr_max_ma_percent = <3500 /* 75% ibus */
                                     2000 /* 85% ibus */>;
		oplus,subboard_ntc_abnormal_current = <7300>;
		oplus,ufcs_warm_allow_vol = <4000>;
		oplus,ufcs_warm_allow_soc = <55>;
		oplus,ufcs_strategy_normal_current = <10900>;
		oplus,ufcs_over_high_or_low_current = <10900>;
		oplus,ufcs_timeout_third = <17208>;
		oplus,ufcs_timeout_oplus = <17208>;
		oplus,ufcs_ibat_over_third = <5400>;
		oplus,ufcs_ibat_over_oplus = <12300>;
		oplus,ufcs_ibus_over_oplus = <12300>;
		oplus,ufcs_full_cool_sw_vbat = <4570>;
		oplus,ufcs_full_normal_sw_vbat = <4570>;
		oplus,ufcs_full_normal_hw_vbat = <4580>;
		oplus,ufcs_full_warm_vbat = <4130>;
		oplus,ufcs_full_cool_sw_vbat_third = <4080>;
		oplus,ufcs_full_normal_sw_vbat_third= <4520>;
		oplus,ufcs_full_normal_hw_vbat_third = <4560>;
		oplus,ufcs_strategy_batt_high_temp = <420 430 435 395 420 430>;
		oplus,ufcs_strategy_high_current = <5500 3500 2000 10900 5500 3500>;
		oplus,ufcs_little_cool_high_temp = <210>;
		oplus,curve_strategy_name = "pps_ufcs_curve_v2";
		oplus_spec,ufcs_high_soc = <90>;
		oplus_spec,ufcs_high_soc_third = <85>;
		oplus_spec,ufcs_low_temp = <50>;
		oplus,ufcs_charge_strategy_temp = <50 50 120 160 350 440 510>;
		oplus,plc_strategy-data = <&oplus_ufcs_step_strategy &cp_2t1_simple_strategy>;
		oplus,plc_strategy-names = "default", "third";
		oplus,ufcs_watt_third = <44000>;

 		oplus,temperature_strategy_name = "cgcl";
		oplus,temperature_strategy_data = <OPLUS_STRATEGY_USE_SHELL_TEMP
						0   420 10900 1 0
						395 430 5500 2 0
						420 435 3500 3 1
						430 440 2000 4 2>;

		ufcs_oplus_lcf_strategy {
			oplus,temp_type = <OPLUS_STRATEGY_USE_SHELL_TEMP>;
			oplus,temp_range = <0 50 120 160 210 380 440>;

			strategy_temp_range_curves {
				strategy_temp_range_t0 =	<150 4520 0
								 125 4510 0
								 100 4500 0
								 75  4490 0
								 50  4480 1>;
				strategy_temp_range_t1 =	<380 4570 0
								 345 4565 0
								 310 4550 0
								 275 4540 0
								 240 4530 1>;
				strategy_temp_range_t2 =	<480 4570 0
								 435 4565 0
								 390 4550 0
								 345 4540 0
								 300 4530 1>;
				strategy_temp_range_t3 =	<590 4570 0
								 545 4565 0
								 500 4550 0
								 455 4540 0
								 410 4530 1>;
				strategy_temp_range_t4 =	<1000 4570 0
								 950 4565 0
								 850  4550 0
								 750  4540 0
								 600  4530 1>;
				strategy_temp_range_t5 =	<1450 4553 0
								 1250 4550 0
								 1200 4548 0
								 1150 4540 0
								 1000 4515 1>;
			};
		};

		ufcs_third_lcf_strategy {
			oplus,temp_type = <OPLUS_STRATEGY_USE_SHELL_TEMP>;
			oplus,temp_range = <0 50 120 160 210 380 440>;

			strategy_temp_range_curves {
				strategy_temp_range_t0 =	<150 4520 0
								 125 4510 0
								 100 4500 0
								 75  4490 0
								 50  4480 1>;
				strategy_temp_range_t1 =	<880 4080 0
								 845 4075 0
								 810 4060 0
								 775 4050 0
								 740 4040 1>;
				strategy_temp_range_t2 =	<880 4180 0
								 835 4175 0
								 790 4160 0
								 745 4150 0
								 700 4140 1>;
				strategy_temp_range_t3 =	<890 4520 0
								 845 4515 0
								 800 4500 0
								 755 4490 0
								 710 4480 1>;
				strategy_temp_range_t4 =	<900 4520 0
								 850  4515 0
								 750  4500 0
								 650  4490 0
								 500  4480 1>;
				strategy_temp_range_t5 =	<750 4483 0
								 550  4480 0
								 500  4478 0
								 450  4470 0
								 300  4445 1>;
			};
		};

		ufcs_charge_third_strategy {
			oplus,temp_type = <OPLUS_STRATEGY_USE_SHELL_TEMP>;
			oplus,soc_range = <0 20 35 55 75 85 90>;
			oplus,temp_range = <0 50 120 160 210 350 440 510>;

			strategy_soc_range_min {
				strategy_temp_little_cold =	<11000 4140 1200 0 0
								11000 4150 1000 1 0>;
				strategy_temp_cool =		<11000 4070 1500 0 0
								11000 4080 1000 1 0>;
				strategy_temp_little_cool =	<11000 4080 3200 0 0
								11000 4080 3000 0 0
								11000 4080 2500 0 0
								11000 4080 2000 0 0
								11000 4170 1500 0 0
								11000 4180 1000 1 0>;
				strategy_temp_little_cool_high = <11000 4080 3800 0 0
								11000 4080 3500 0 0
								11000 4180 3200 0 0
								11000 4180 3000 0 0
								11000 4180 2500 0 0
								11000 4180 2000 0 0
								11000 4510 1500 0 0
								11000 4520 1000 1 0>;
				strategy_temp_normal_low =	<11000 4510 4000 0 0
								11000 4510 3500 0 0
								11000 4510 3000 0 0
								11000 4510 2500 0 0
								11000 4510 2000 0 0
								11000 4510 1500 0 0
								11000 4520 1000 1 0>;
				strategy_temp_normal_high =	<11000 4490 4000 0 0
								11000 4490 3500 0 0
								11000 4490 3000 0 0
								11000 4490 2500 0 0
								11000 4490 2000 0 0
								11000 4490 1500 0 0
								11000 4500 1000 1 0>;
				strategy_temp_warm =		<11000 4120 1800 0 0
								11000 4120 1500 0 0
								11000 4130 1000 1 0>;
			};
			strategy_soc_range_low {
				strategy_temp_little_cold =	<11000 4140 1200 0 0
								11000 4150 1000 1 0>;
				strategy_temp_cool =		<11000 4070 1500 0 0
								11000 4080 1000 1 0>;
				strategy_temp_little_cool =	<11000 4080 3200 0 0
								11000 4080 3000 0 0
								11000 4080 2500 0 0
								11000 4080 2000 0 0
								11000 4170 1500 0 0
								11000 4180 1000 1 0>;
				strategy_temp_little_cool_high = <11000 4080 3800 0 0
								11000 4080 3500 0 0
								11000 4180 3200 0 0
								11000 4180 3000 0 0
								11000 4180 2500 0 0
								11000 4180 2000 0 0
								11000 4510 1500 0 0
								11000 4520 1000 1 0>;
				strategy_temp_normal_low =	<11000 4510 4000 0 0
								11000 4510 3500 0 0
								11000 4510 3000 0 0
								11000 4510 2500 0 0
								11000 4510 2000 0 0
								11000 4510 1500 0 0
								11000 4520 1000 1 0>;
				strategy_temp_normal_high =	<11000 4490 4000 0 0
								11000 4490 3500 0 0
								11000 4490 3000 0 0
								11000 4490 2500 0 0
								11000 4490 2000 0 0
								11000 4490 1500 0 0
								11000 4500 1000 1 0>;
				strategy_temp_warm =		<11000 4120 1800 0 0
								11000 4120 1500 0 0
								11000 4130 1000 1 0>;
			};
			strategy_soc_range_mid_low {
				strategy_temp_little_cold =	<11000 4140 1200 0 0
								11000 4150 1000 1 0>;
				strategy_temp_cool =		<11000 4070 1500 0 0
								11000 4080 1000 1 0>;
				strategy_temp_little_cool =	<11000 4080 3200 0 0
								11000 4080 3000 0 0
								11000 4080 2500 0 0
								11000 4080 2000 0 0
								11000 4170 1500 0 0
								11000 4180 1000 1 0>;
				strategy_temp_little_cool_high = <11000 4080 3800 0 0
								11000 4080 3500 0 0
								11000 4180 3200 0 0
								11000 4180 3000 0 0
								11000 4180 2500 0 0
								11000 4180 2000 0 0
								11000 4510 1500 0 0
								11000 4520 1000 1 0>;
				strategy_temp_normal_low =	<11000 4510 4000 0 0
								11000 4510 3500 0 0
								11000 4510 3000 0 0
								11000 4510 2500 0 0
								11000 4510 2000 0 0
								11000 4510 1500 0 0
								11000 4520 1000 1 0>;
				strategy_temp_normal_high =	<11000 4490 4000 0 0
								11000 4490 3500 0 0
								11000 4490 3000 0 0
								11000 4490 2500 0 0
								11000 4490 2000 0 0
								11000 4490 1500 0 0
								11000 4500 1000 1 0>;
				strategy_temp_warm =		<11000 4120 1800 0 0
								11000 4120 1500 0 0
								11000 4130 1000 1 0>;
			};
			strategy_soc_range_mid {
				strategy_temp_little_cold =	<11000 4140 1200 0 0
								11000 4150 1000 1 0>;
				strategy_temp_cool =		<11000 4070 1500 0 0
								11000 4080 1000 1 0>;
				strategy_temp_little_cool =	<11000 4080 3000 0 0
								11000 4080 2500 0 0
								11000 4080 2000 0 0
								11000 4170 1500 0 0
								11000 4180 1000 1 0>;
				strategy_temp_little_cool_high = <11000 4180 3000 0 0
								11000 4180 2500 0 0
								11000 4180 2000 0 0
								11000 4510 1500 0 0
								11000 4520 1000 1 0>;
				strategy_temp_normal_low =	<11000 4510 3500 0 0
								11000 4510 3000 0 0
								11000 4510 2500 0 0
								11000 4510 2000 0 0
								11000 4510 1500 0 0
								11000 4520 1000 1 0>;
				strategy_temp_normal_high =	<11000 4490 4000 0 0
								11000 4490 3500 0 0
								11000 4490 3000 0 0
								11000 4490 2500 0 0
								11000 4490 2000 0 0
								11000 4490 1500 0 0
								11000 4500 1000 1 0>;
				strategy_temp_warm =		<11000 4120 1900 0 0
								11000 4120 1500 0 0
								11000 4130 1000 1 0>;
			};
			strategy_soc_range_mid_high {
				strategy_temp_little_cold =	<11000 4140 1200 0 0
								11000 4150 1000 1 0>;
				strategy_temp_cool =		<11000 4070 1500 0 0
								11000 4080 1000 1 0>;
				strategy_temp_little_cool =	<11000 4080 2000 0 0
								11000 4170 1500 0 0
								11000 4180 1000 1 0>;
				strategy_temp_little_cool_high = <11000 4180 2000 0 0
								11000 4510 1500 0 0
								11000 4520 1000 1 0>;
				strategy_temp_normal_low =	<11000 4510 2500 0 0
								11000 4510 2000 0 0
								11000 4510 1500 0 0
								11000 4520 1000 1 0>;
				strategy_temp_normal_high =	<11000 4490 2500 0 0
								11000 4490 2000 0 0
								11000 4490 1500 0 0
								11000 4500 1000 1 0>;
				strategy_temp_warm =		<11000 4120 1900 0 0
								11000 4120 1500 0 0
								11000 4130 1000 1 0>;
			};
			strategy_soc_range_high {
				strategy_temp_little_cold =	<11000 4150 1000 1 0>;
				strategy_temp_cool =		<11000 4500 1000 1 0>;
				strategy_temp_little_cool =	<11000 4500 1000 1 0>;
				strategy_temp_little_cool_high = <11000 4500 1000 1 0>;
				strategy_temp_normal_low =	<11000 4500 1000 1 0>;
				strategy_temp_normal_high =	<11000 4475 1000 1 0>;
				strategy_temp_warm =		<11000 4130 1000 1 0>;
			};
		};

		ufcs_charge_oplus_strategy {
			oplus,temp_type = <OPLUS_STRATEGY_USE_SHELL_TEMP>;
			oplus,soc_range = <0 20 35 55 75 85 90>;
			oplus,temp_range = <0 50 120 160 210 350 440 510>;

			strategy_soc_range_min {
				strategy_temp_little_cold =	<11000 4150 1200 0 0
								11000 4150 1000 0 0
								11000 4570 500 1 0>;
				strategy_temp_cool =		<11000 4080 1500 0 0
								11000 4080 1000 0 0
								11000 4180 800 0 0
								11000 4570 500 1 0>;
				strategy_temp_little_cool =	<11000 4080 3200 0 0
								11000 4080 3000 0 0
								11000 4080 2500 0 0
								11000 4080 2000 0 0
								11000 4180 1500 0 0
								11000 4180 1000 0 0
								11000 4560 800 0 0
								11000 4570 600 1 0>;
				strategy_temp_little_cool_high = <11000 4080 3800 0 0
								11000 4080 3500 0 0
								11000 4180 3200 0 0
								11000 4180 3000 0 0
								11000 4180 2500 0 0
								11000 4180 2000 0 0
								11000 4560 1500 0 0
								11000 4560 1000 0 0
								11000 4570 700 1 0>;
				strategy_temp_normal_low =	<11000 4110 10900 0 30
								11000 4120 10000 0 0
								11000 4120  9100 0 0
								11000 4120  8500 0 0
								11000 4330  8000 0 0
								11000 4330  7500 0 0
								11000 4330  7000 0 0
								11000 4330  6500 0 0
								11000 4470  6400 0 0
								11000 4470  6000 0 0
								11000 4530  5600 0 0
								11000 4530  5500 0 0
								11000 4530  5000 0 0
								11000 4560  4800 0 0
								11000 4560  4500 0 0
								11000 4560  4000 0 0
								11000 4560  3500 0 0
								11000 4560  3000 0 0
								11000 4560  2500 0 0
								11000 4560  2000 0 0
								11000 4560  1500 0 0
								11000 4570  1100 1 0>;
				strategy_temp_normal_high =	<11000 4110 10900 0 30
								11000 4120 10000 0 0
								11000 4120  9100 0 0
								11000 4120  8500 0 0
								11000 4330  8000 0 0
								11000 4330  7500 0 0
								11000 4330  7000 0 0
								11000 4330  6500 0 0
								11000 4470  6400 0 0
								11000 4470  6000 0 0
								11000 4530  5600 0 0
								11000 4530  5500 0 0
								11000 4530  5000 0 0
								11000 4560  4800 0 0
								11000 4560  4500 0 0
								11000 4560  4000 0 0
								11000 4560  3500 0 0
								11000 4560  3000 0 0
								11000 4560  2500 0 0
								11000 4560  2000 0 0
								11000 4570  1700 1 0>;
				strategy_temp_warm =		<11000 4120 1800 0 0
								11000 4120 1500 0 0
								11000 4120 1000 0 0
								11000 4130 500 1 0>;
			};
			strategy_soc_range_low {
				strategy_temp_little_cold =	<11000 4150 1200 0 0
								11000 4150 1000 0 0
								11000 4570 500 1 0>;
				strategy_temp_cool =		<11000 4080 1500 0 0
								11000 4080 1000 0 0
								11000 4180 800 0 0
								11000 4570 500 1 0>;
				strategy_temp_little_cool =	<11000 4080 3200 0 0
								11000 4080 3000 0 0
								11000 4080 2500 0 0
								11000 4080 2000 0 0
								11000 4180 1500 0 0
								11000 4180 1000 0 0
								11000 4560 800 0 0
								11000 4570 600 1 0>;
				strategy_temp_little_cool_high = <11000 4080 3800 0 0
								11000 4080 3500 0 0
								11000 4180 3200 0 0
								11000 4180 3000 0 0
								11000 4180 2500 0 0
								11000 4180 2000 0 0
								11000 4560 1500 0 0
								11000 4560 1000 0 0
								11000 4570 700 1 0>;
				strategy_temp_normal_low =	<11000 4110 10900 0 30
								11000 4120 10000 0 0
								11000 4120  9100 0 0
								11000 4120  8500 0 0
								11000 4330  8000 0 0
								11000 4330  7500 0 0
								11000 4330  7000 0 0
								11000 4330  6500 0 0
								11000 4470  6400 0 0
								11000 4470  6000 0 0
								11000 4530  5600 0 0
								11000 4530  5500 0 0
								11000 4530  5000 0 0
								11000 4560  4800 0 0
								11000 4560  4500 0 0
								11000 4560  4000 0 0
								11000 4560  3500 0 0
								11000 4560  3000 0 0
								11000 4560  2500 0 0
								11000 4560  2000 0 0
								11000 4560  1500 0 0
								11000 4570  1100 1 0>;
				strategy_temp_normal_high =	<11000 4110 10900 0 30
								11000 4120 10000 0 0
								11000 4120  9100 0 0
								11000 4120  8500 0 0
								11000 4330  8000 0 0
								11000 4330  7500 0 0
								11000 4330  7000 0 0
								11000 4330  6500 0 0
								11000 4470  6400 0 0
								11000 4470  6000 0 0
								11000 4530  5600 0 0
								11000 4530  5500 0 0
								11000 4530  5000 0 0
								11000 4560  4800 0 0
								11000 4560  4500 0 0
								11000 4560  4000 0 0
								11000 4560  3500 0 0
								11000 4560  3000 0 0
								11000 4560  2500 0 0
								11000 4560  2000 0 0
								11000 4570  1700 1 0>;
				strategy_temp_warm =		<11000 4120 1800 0 0
								11000 4120 1500 0 0
								11000 4120 1000 0 0
								11000 4130 500 1 0>;
			};
			strategy_soc_range_mid_low {
				strategy_temp_little_cold =	<11000 4150 1200 0 0
								11000 4150 1000 0 0
								11000 4570 500 1 0>;
				strategy_temp_cool =		<11000 4080 1500 0 0
								11000 4080 1000 0 0
								11000 4180 800 0 0
								11000 4570 500 1 0>;
				strategy_temp_little_cool =	<11000 4080 3200 0 0
								11000 4080 3000 0 0
								11000 4080 2500 0 0
								11000 4080 2000 0 0
								11000 4180 1500 0 0
								11000 4180 1000 0 0
								11000 4560 800 0 0
								11000 4570 600 1 0>;
				strategy_temp_little_cool_high = <11000 4080 3800 0 0
								11000 4080 3500 0 0
								11000 4180 3200 0 0
								11000 4180 3000 0 0
								11000 4180 2500 0 0
								11000 4180 2000 0 0
								11000 4560 1500 0 0
								11000 4560 1000 0 0
								11000 4570 700 1 0>;
				strategy_temp_normal_low =	<11000 4110 10900 0 30
								11000 4120 10000 0 0
								11000 4120  9100 0 0
								11000 4120  8500 0 0
								11000 4330  8000 0 0
								11000 4330  7500 0 0
								11000 4330  7000 0 0
								11000 4330  6500 0 0
								11000 4470  6400 0 0
								11000 4470  6000 0 0
								11000 4530  5600 0 0
								11000 4530  5500 0 0
								11000 4530  5000 0 0
								11000 4560  4800 0 0
								11000 4560  4500 0 0
								11000 4560  4000 0 0
								11000 4560  3500 0 0
								11000 4560  3000 0 0
								11000 4560  2500 0 0
								11000 4560  2000 0 0
								11000 4560  1500 0 0
								11000 4570  1100 1 0>;
				strategy_temp_normal_high =	<11000 4110 10900 0 30
								11000 4120 10000 0 0
								11000 4120  9100 0 0
								11000 4120  8500 0 0
								11000 4330  8000 0 0
								11000 4330  7500 0 0
								11000 4330  7000 0 0
								11000 4330  6500 0 0
								11000 4470  6400 0 0
								11000 4470  6000 0 0
								11000 4530  5600 0 0
								11000 4530  5500 0 0
								11000 4530  5000 0 0
								11000 4560  4800 0 0
								11000 4560  4500 0 0
								11000 4560  4000 0 0
								11000 4560  3500 0 0
								11000 4560  3000 0 0
								11000 4560  2500 0 0
								11000 4560  2000 0 0
								11000 4570  1700 1 0>;
				strategy_temp_warm =		<11000 4120 1800 0 0
								11000 4120 1500 0 0
								11000 4120 1000 0 0
								11000 4130 500 1 0>;
			};
			strategy_soc_range_mid {
				strategy_temp_little_cold =	<11000 4150 1200 0 0
								11000 4150 1000 0 0
								11000 4570 500 1 0>;
				strategy_temp_cool =		<11000 4080 1500 0 0
								11000 4080 1000 0 0
								11000 4180 800 0 0
								11000 4570 500 1 0>;
				strategy_temp_little_cool =	<11000 4080 3200 0 0
								11000 4080 3000 0 0
								11000 4080 2500 0 0
								11000 4080 2000 0 0
								11000 4180 1500 0 0
								11000 4180 1000 0 0
								11000 4560 800 0 0
								11000 4570 600 1 0>;
				strategy_temp_little_cool_high = <11000 4080 3800 0 0
								11000 4080 3500 0 0
								11000 4180 3200 0 0
								11000 4180 3000 0 0
								11000 4180 2500 0 0
								11000 4180 2000 0 0
								11000 4560 1500 0 0
								11000 4560 1000 0 0
								11000 4570 700 1 0>;
				strategy_temp_normal_low =	<11000 4560  4500 0 0
								11000 4560  4000 0 0
								11000 4560  3500 0 0
								11000 4560  3000 0 0
								11000 4560  2500 0 0
								11000 4560  2000 0 0
								11000 4560  1500 0 0
								11000 4570  1100 1 0>;
				strategy_temp_normal_high =	<11000 4530  5000 0 0
								11000 4560  4800 0 0
								11000 4560  4500 0 0
								11000 4560  4000 0 0
								11000 4560  3500 0 0
								11000 4560  3000 0 0
								11000 4560  2500 0 0
								11000 4560  2000 0 0
								11000 4570  1700 1 0>;
				strategy_temp_warm =		<11000 4120 1800 0 0
								11000 4120 1500 0 0
								11000 4120 1000 0 0
								11000 4130 500 1 0>;
			};
			strategy_soc_range_mid_high {
				strategy_temp_little_cold =	<11000 4150 1200 0 0
								11000 4150 1000 0 0
								11000 4570 500 1 0>;
				strategy_temp_cool =		<11000 4080 1500 0 0
								11000 4080 1000 0 0
								11000 4180 800 0 0
								11000 4570 500 1 0>;
				strategy_temp_little_cool =	<11000 4080 3000 0 0
								11000 4080 2500 0 0
								11000 4080 2000 0 0
								11000 4180 1500 0 0
								11000 4180 1000 0 0
								11000 4560 800 0 0
								11000 4570 600 1 0>;
				strategy_temp_little_cool_high = <11000 4180 3000 0 0
								11000 4180 2500 0 0
								11000 4180 2000 0 0
								11000 4560 1500 0 0
								11000 4560 1000 0 0
								11000 4570 700 1 0>;
				strategy_temp_normal_low =	<11000 4560  3500 0 0
								11000 4560  3000 0 0
								11000 4560  2500 0 0
								11000 4560  2000 0 0
								11000 4560  1500 0 0
								11000 4570  1100 1 0>;
				strategy_temp_normal_high =	<11000 4560  3500 0 0
								11000 4560  3000 0 0
								11000 4560  2500 0 0
								11000 4560  2000 0 0
								11000 4570  1700 1 0>;
				strategy_temp_warm =		<11000 4120 1800 0 0
								11000 4120 1500 0 0
								11000 4120 1000 0 0
								11000 4130 500 1 0>;
			};
			strategy_soc_range_high {
				strategy_temp_little_cold =	<11000 4150 1200 0 0
								11000 4150 1000 0 0
								11000 4570 500 1 0>;
				strategy_temp_cool =		<11000 4080 1500 0 0
								11000 4080 1000 0 0
								11000 4180 800 0 0
								11000 4570 500 1 0>;
				strategy_temp_little_cool =	<11000 4180 1500 0 0
								11000 4180 1000 0 0
								11000 4560 800 0 0
								11000 4570 600 1 0>;
				strategy_temp_little_cool_high = <11000 4560 1500 0 0
								11000 4560 1000 0 0
								11000 4570 700 1 0>;
				strategy_temp_normal_low =	<11000 4560  2000 0 0
								11000 4560  1500 0 0
								11000 4570  1100 1 0>;
				strategy_temp_normal_high =	<11000 4560  2000 0 0
								11000 4570  1700 1 0>;
				strategy_temp_warm =		<11000 4120 1800 0 0
								11000 4120 1500 0 0
								11000 4120 1000 0 0
								11000 4130 500 1 0>;
			};
		};

		oplus,impedance_node {
			ufcs_input_impedance: ufcs_input_impedance {
				node_name = "ufcs_mos";
				default_impedance_mohm = <0>;
				default_curr_ma = <10900>;
				current_drop_table = <
					125 10000
					130 8000
					190 5000
					250 4000
					340 3000
					380 2000
					480 0
				>;
			};
		};
	};
	oplus_ufcs_impedance_check: oplus,ufcs_impedance_check {
		compatible = "oplus,impedance_check";

		oplus,impedance_unit {
			oplus_ufcs_impedance_unit: oplus,ufcs_impedance_unit {
				uint_name = "ufcs";
				default_curr_ma = <10900>;
				impedance_node = <&ufcs_input_impedance>;
			};
		};
	};
};
//#endif OPLUS_FEATURE_CHG_BASIC /*for ufcs config*/



//#ifdef OPLUS_FEATURE_CHG_BASIC /* BSP.CHG.Basic, 2023/04/19, sjc Add for wls charging */
//for wls charging config
&battery_charger {
	oplus,wls_boost_vol_start_mv = <7000>;
	oplus,wls_boost_vol_max_mv = <7000>;
	oplus,wls_boost_src = <1>;/*0:pmic otg, 1:pmic wls */
};

&soc {
	oplus_chg_wls: oplus,chg_wls {
		status = "ok";
		compatible = "oplus,chg_wls";

		oplus,rx_ic = <&oplus_virtual_rx>;
		oplus,nor_ic = <&oplus_virtual_buck>;
		oplus,fast_ic = <&oplus_virtual_cp>;

		oplus,support_fastchg;
		oplus,support_epp_plus;
		oplus,support_wls_chg_bcc;
		oplus,support_acdrv_no_ext_boost;
		oplus,support_no_hw_interlock;

		oplus,max-voltage-mv = <4580>;
		oplus,fastchg_curr_max_ma = <5000>;
		oplus,verity_curr_max_ma = <5000>;
		oplus,wls-fast-chg-call-on-curr-ma = <600>;
		oplus,wls-fast-chg-camera-on-curr-ma = <600>;
		oplus,wls_power_mw = <50000>;
		oplus,wls_phone_id = <0x1E>;
		oplus,wls-bcc-fcc-to-icl-factor = <1>;
		oplus,normal_high_batt_temp = <210>;
		oplus,little_warm_batt_temp = <350>;
		oplus,wls_boost_curr_limit_ma = <1500>;
		oplus,rx_protocol_version = <30>;
		oplus,rx_coil = <48>;
		oplus,vbridge_ratio = <40>;
		oplus,magcvr_vbridge_ratio = <40>;
		oplus,non_mag_power_mw = <20000>;
		/*
		 * | temp_min | temp_max | target_curr_ma(mA) |
		 *
		 * temp_min: Switch to the previous level when the temperature is lower
		 *           than this value. If it is 0, do not switch.
		 * temp_max: Switch to the next level when the temperature is greater
		 *           than this value
		 */
		oplus,epp_plus-skin-step = <0 360 1700
					    350 380 1700
					    360 390 1700
					    370 410 1700>;
		oplus,epp-skin-step = <0 390 1500
				       360 400 1500>;
		oplus,bpp-skin-step = <0 390 750
				       370 400 750>;
		oplus,epp_plus-led-on-skin-step = <0 390 1700
						   380 500 1700>;
		oplus,epp-led-on-skin-step = <0 390 1500
					      380 500 1500>;

		/*
		 * | cool_temp | heat_temp | curr_data | heat_next_index | cool_next_index |
		 */
		oplus,wls-fast-chg-led-off-strategy-data = <0 410 5000 1 0
							    390 450 2400 1 0>;
		oplus,wls-fast-chg-led-on-strategy-data = <0 340 5000 1 0
							   330 360 2000 2 0
							   350 380 1600 3 1
							   370 400 1200 3 2>;

		oplus,iclmax-ma = <300 750 750 750 750 750 750 750 750 300    /*wls-bpp(mA)*/
				   600 800 1500 1500 1500 1500 1500 1500 800 600    /*wls-epp(mA)*/
				   600 800 1700 1700 1700 1700 1700 1700 800 600    /*wls-epp-plus(mA)*/
				   600 750 1800 1800 1800 1800 1800 1800 750 600    /*wls-airvooc(mA)*/
				   600 800 2000 2500 5000 5000 5000 5000 800 600>;  /*wls-airsvooc(mA)*/
		oplus,iclmax-batt-high-ma = <300 400 750 750 750 750 750 750 750 300    /*wls-bpp(mA)*/
					     600 500 800 1500 1500 1500 1500 1500 800 600    /*wls-epp(mA)*/
					     600 500 800 1700 1700 1700 1700 1700 800 600    /*wls-epp-plus(mA)*/
					     600 400 750 1800 1800 1800 1800 1800 750 600    /*wls-airvooc(mA)*/
					     600 400 2000 2500 5000 5000 5000 5000 800 600>;  /*wls-airsvooc(mA)*/

		/*
		 * | temp_min | temp_max | target_curr_ma | vol_max_mv | need_wait |
		 * temp_min/temp_max: not use here
		 * target_curr_ma: wls icl when vbat < vol_max_mv
		 * vol_max_mv: the last value is always 5000mV(must be greater than the max-vbat)
		 * need_wait: not use here
		 * if there is non_ffc_strategy, use the parameter in non_ffc_strategy
		 */
		non-ffc-bpp =		<0 0 750 5000 0>;
		non-ffc-epp =		<0 0 1500 4385 0
					 0 0 800 5000 0>;
		non-ffc-epp-plus =	<0 0 1700 4380 0
					 0 0 1500 4385 0
					 0 0 800 5000 0>;
		non-ffc-airvooc =	<0 0 2000 4375 0
					 0 0 800 5000 0>;
		non-ffc-airsvooc =	<0 0 2000 4375 0
					 0 0 800 5000 0>;
		/*
		 * | temp_min | temp_max | target_curr_ma | vol_max_mv | need_wait |
		 * temp_min: Switch to the previous level when the temperature is lower
		 *           than this value. If it is 0, do not switch.
		 * temp_max: Switch to the next level when the temperature is higher
		 *           than this value
		 * target_curr_ma: wls icl when vbat > vol_max_mv
		 * vol_max_mv: Maximum battery voltage.
		 * need_wait: not use here
		 */
		cv-bpp = 	<(-100) 0 250 4520 0
				0 350 400 4520 0
				350 450 400 4500 0
				450 530 400 4130 0>;
		cv-epp =	<(-100) 0 600 4520 0
				0 350 600 4520 0
				350 450 600 4500 0
				450 530 600 4130 0>;
		cv-epp-plus =	<(-100) 0 600 4520 0
				0 350 600 4520 0
				350 450 600 4500 0
				450 530 600 4130 0>;
		cv-airvooc =	<(-100) 0 600 4520 0
				0 350 600 4520 0
				350 450 600 4500 0
				450 530 600 4130 0>;
		cv-airsvooc =	<(-100) 0 600 4520 0
				0 350 600 4520 0
				350 450 600 4500 0
				450 530 600 4130 0>;

		cv-bpp-high-batt = 	<(-100) 0 250 4520 0
				0 350 400 4520 0
				350 450 400 4500 0
				450 530 400 4130 0>;
		cv-epp-high-batt =	<(-100) 0 300 4520 0
				0 350 600 4520 0
				350 450 600 4500 0
				450 530 600 4130 0>;
		cv-epp-plus-high-batt =	<(-100) 0 300 4520 0
				0 350 600 4520 0
				350 450 600 4500 0
				450 530 600 4130 0>;
		cv-airvooc-high-batt =	<(-100) 0 300 4520 0
				0 350 600 4520 0
				350 450 600 4500 0
				450 530 600 4130 0>;
		cv-airsvooc-high-batt =	<(-100) 0 300 4520 0
				0 350 600 4520 0
				350 450 600 4500 0
				450 530 600 4130 0>;

		oplus,cool-down-12v-thr = <2>;//switch to 12V level
		cool-down-bpp = <0 750 750 750 750 750 750>;
		cool-down-epp = <0 800 800 1500 1500 1500 1500>;
		cool-down-epp-plus = <0 800 800 1500 1500 1500 1700>;
		cool-down-airvooc = <0 800 800 1800 1800 1800 1800>;
		cool-down-airsvooc = <0 800 2000 1500 1500 2000 2500 2500 2500 2500 2500 2500 2500>;

		/*
		 * | bcc_stop_curr |
		 * The three parameters of each array
		 * correspond to three temperature intervals: 0-5; 5-12; 12-44
		 */
		bcc_stop_curr_0_to_30 = <1000 1000 1000 1000 1000>;
		bcc_stop_curr_30_to_70 = <1000 1000 1000 1000 1000>;
		bcc_stop_curr_70_to_90 = <1000 1000 1000 1000 1000>;

		/*
		 * | curr_ma | fallback_step | switch_to_bpp
		 * curr_ma: wls icl in this step
		 * fallback_step: 0: don't fallback when CEP is OK
		 *                1/2...: fallback to 1st/2nd step when CEP is OK
		 * switch_to_bpp: reach the final step, switch to bpp when CEP is not OK
		 */
		skewing-epp =		<1500 0 0
					 1100 0 0
					 800 1 0>;
		skewing-epp-plus =	<1700 0 0
					 1500 0 0
					 1100 2 0
					 800 3 0>;//fallback to 800(2nd step) when CEP is OK at this step
		skewing-airvooc =	<1800 0 0
					 750 0 0>;

		/* fod parameter*/
		/*
		 * oplus,fastchg-match-q: | wls_base(dock) id | q value | f value
		 * oplus,fod-parm-array-row-len: dock id len(1) + oplus,fastchg-fod-parm-len, only for new projects
		 *                               old projects: WLS_FOD_PARM_LEN_MAX is 32
		 *                               new projects: WLS_FOD_PARM_LEN_MAX is 64
		 * oplus,fastchg-fod-parm-len: fod parm length, DO NOT include wls_base(dock) id
		 * oplus,fastchg-fod-parm: | wls_base(dock) id | WLS_FOD_PARM_LEN_MAX(32) pieces of fod parms |
		 *                         default wls_base id is 0xff
		 * oplus,disable-fod-parm: disable fod parm, DO NOT include wls_base(dock) id
		 */
		oplus,fastchg-fod-enable;
		oplus,fastchg-match-q = /bits/ 8 <0x00 0x41 0x55
						  0x01 0x41 0x55
						  0x02 0x50 0x55
						  0x03 0x4b 0x55
						  0x04 0x10 0x5F
						  0x1f 0x2d 0x55>;
		oplus,fastchg-match-q-magcvr = /bits/ 8 <0x00 0x41 0x55
							 0x01 0x41 0x55
							 0x02 0x40 0x55
							 0x03 0x40 0x55
							 0x04 0x05 0x5F
							 0x1f 0x2d 0x55>;
		oplus,fod-parm-array-row-len = <33>;
		oplus,fastchg-fod-parm-len = <32>;
		/*oplus,fastchg-fod-parm = /bits/ 8 <0xff  0xff 0x7f 0xff 0x7f 0xa1 0x10 0x9e 0x7f 0xae 0x00 0xa8 0x7f 0xa7 0x40
							 0xff 0xff 0xff 0xff 0xff 0xff 0xff 0xff 0xff 0xff 0xff 0xff 0xff 0xff 0xff 0xff 0xff 0xff>;*/
		/*wls_base(dock) id | fod parms*/
		oplus,fastchg-fod-parm =	/bits/ 8 <0x01  0x90 0x32 0x90 0x32 0x90 0x32 0x90 0x32 0x91 0x32 0x91 0x37 0x92 0x3c 0x92 0x3c
								0x93 0x3c 0x96 0x3c 0x99 0x3c 0x9d 0x46 0xa2 0x55 0xa4 0x5a 0xa4 0x5a 0xa4 0x5a
							  0x02  0x8f 0x37 0x8f 0x37 0x8f 0x37 0x8f 0x41 0x8e 0x3c 0x91 0x46 0x93 0x4b 0x94 0x46
								0x95 0x4b 0x97 0x46 0x9a 0x46 0x9d 0x50 0x9f 0x50 0xab 0x5a 0xab 0x5a 0xab 0x5a
							  0x03  0x8c 0x50 0x8d 0x50 0x8f 0x55 0x8f 0x55 0x8f 0x5a 0x8f 0x64 0x90 0x64 0x91 0x64
								0x93 0x64 0x96 0x64 0x99 0x5a 0x9a 0x5a 0xa3 0x5a 0xa4 0x5a 0xa4 0x5a 0xa4 0x5a
							  0x04  0x64 0x05 0x64 0x0f 0x64 0x0a 0x64 0x19 0x69 0x1e 0x72 0x3c 0x78 0x46 0x7f 0x4b
								0x83 0x4b 0x86 0x4b 0x8b 0x4b 0x91 0x46 0x9e 0x4b 0x9e 0x4b 0xa0 0x4b 0xa0 0x4b
							  0x1f  0x90 0x46 0x8e 0x3b 0x8e 0x37 0x96 0x5c 0x8f 0x37 0x8f 0x2d 0x8f 0x42 0x8f 0x42
								0x8f 0x4e 0x95 0x40 0x96 0x40 0x9b 0x32 0xa2 0x6e 0xa3 0x75 0xa3 0x64 0xa3 0x64
							  0xff  0x90 0x46 0x8e 0x3b 0x8e 0x37 0x90 0x34 0x8f 0x37 0x8f 0x41 0x8f 0x60 0x8f 0x60
								0x8f 0x62 0x95 0x54 0x96 0x54 0x9b 0x32 0xa2 0x6e 0xa3 0x75 0xa3 0x64 0xa3 0x64>;
		oplus,fastchg-fod-parm-magcvr = /bits/ 8 <0x01  0x90 0x28 0x90 0x28 0x90 0x28 0x90 0x28 0x91 0x28 0x91 0x2d 0x92 0x32 0x92 0x32
								0x93 0x32 0x96 0x32 0x99 0x32 0x9d 0x3c 0xa2 0x4b 0xa4 0x50 0xa4 0x50 0xa4 0x50
							  0x02  0x8e 0x32 0x8e 0x32 0x8e 0x32 0x8e 0x32 0x8f 0x41 0x90 0x46 0x92 0x50 0x93 0x5a
								0x94 0x5f 0x95 0x69 0x97 0x69 0x99 0x73 0xab 0x73 0xac 0x78 0xac 0x78 0xac 0x78
							  0x03  0x8e 0x2d 0x8e 0x2d 0x8e 0x2d 0x8e 0x2d 0x8e 0x2d 0x8f 0x32 0x91 0x3c 0x91 0x3c
								0x92 0x46 0x96 0x46 0x96 0x46 0x98 0x4b 0xa4 0x69 0xa4 0x69 0xa4 0x69 0xa4 0x69
							  0x04  0x7d 0x28 0x7f 0x37 0x81 0x37 0x83 0x32 0x85 0x32 0x87 0x32 0x88 0x5a 0x8a 0x5a
								0x8c 0x5a 0x91 0x5a 0x93 0x5a 0x94 0x5a 0xa0 0x6e 0xa1 0x6e 0xa1 0x6e 0xa1 0x6e
							  0x1f  0x90 0x46 0x8e 0x3e 0x8e 0x3c 0x90 0x3a 0x91 0x2e 0x92 0x62 0x97 0x59 0x97 0x5c
								0x98 0x63 0x99 0x63 0x99 0x63 0x9c 0x5a 0xa6 0x70 0xa7 0x6a 0xa7 0x6a 0xa7 0x6a
							  0xff  0x91 0x61 0x8f 0x56 0x8f 0x56 0x91 0x57 0x92 0x58 0x92 0x62 0x98 0x64 0x98 0x69
								0x98 0x69 0x99 0x63 0x99 0x63 0x9d 0x6d 0xa7 0x7c 0xa9 0x7c 0xa9 0x7c 0xa9 0x7c>;
		oplus,bpp-fod-parm = 		/bits/ 8 <0xff  0x7e 0x14 0x7e 0x13 0x7f 0x17 0x7f 0x17 0x7f 0x1b 0x80 0x1d 0x81 0x1f 0x81 0x20
								0xff 0xff 0xff 0xff 0xff 0xff 0xff 0xff 0xff 0xff 0xff 0xff 0xff 0xff 0xff 0xff>;
		oplus,bpp-fod-parm-magcvr =	/bits/ 8 <0xff  0x7e 0x31 0x7e 0x29 0x7f 0x2d 0x7f 0x2e 0x7f 0x31 0x80 0x32 0x81 0x35 0x81 0x35
								0xff 0xff 0xff 0xff 0xff 0xff 0xff 0xff 0xff 0xff 0xff 0xff 0xff 0xff 0xff 0xff>;
		oplus,epp-fod-parm =		/bits/ 8 <0xff  0x7b 0x18 0x7f 0x1b 0x80 0x1b 0x81 0x19 0x83 0x1a 0x84 0x1c 0x85 0x1d 0x85 0x1f
								0xff 0xff 0xff 0xff 0xff 0xff 0xff 0xff 0xff 0xff 0xff 0xff 0xff 0xff 0xff 0xff>;
		oplus,epp-fod-parm-magcvr =	/bits/ 8 <0xff  0x7b 0x26 0x7f 0x28 0x80 0x28 0x81 0x27 0x83 0x27 0x84 0x28 0x85 0x29 0x85 0x2B
								0xff 0xff 0xff 0xff 0xff 0xff 0xff 0xff 0xff 0xff 0xff 0xff 0xff 0xff 0xff 0xff>;
		/*only fod parms*/
		oplus,disable-fod-parm =	/bits/ 8 <0xff 0xff 0xff 0xff 0xff 0xff 0xff 0xff 0xff 0xff 0xff 0xff 0xff 0xff 0xff 0xff
							  0xff 0xff 0xff 0xff 0xff 0xff 0xff 0xff 0xff 0xff 0xff 0xff 0xff 0xff 0xff 0xff>;
		oplus,epp-high-temp-force-bpp-thr = <440>;
		oplus,bpp-vol-mv = <5500>;
		oplus,epp-vol-mv = <6000>;
		oplus,epp_plus-vol-mv = <6000>;
		oplus,vooc-vol-mv = <6400>;
		oplus,svooc-vol-mv = <10000>;
		oplus,fastchg-init-vout-mv = <6400>;
		oplus,full-bridge-vout-mv = <9200>;
		oplus,cp-open-offset-mv = <150>;
		oplus,cp-open-offset-min-mv = <50>;
		oplus,fastch-wait-thr-mv = <4180>;

		oplus,fastchg-max-vbat = <5000 5000 3880 5000 5000 5000 5000 5000 5000 5000>;
		oplus,fastchg-max-soc = <95>;
		oplus,fastchg-max-temp = <440>;
		oplus,strategy_soc = <20 35 55 75 85 95>;
		oplus,boot_quiet_time = <30>;

		/*
		 * | temp_min | temp_max | icl_curr | fcc_curr | need_wait |
		 */
		oplus,wls_epp_strategy =	<0 350 1500 2000 1
						 335 360 1100 1600 1
						 350 460 800 1000 1
						 440 530 400 1000 1>;
		oplus,wls_epp_plus_strategy =	<0 330 1700 2200 1
						 310 350 1500 2000 1
						 335 360 1100 1600 1
						 350 460 800 1000 1
						 440 530 400 1000 1>;
		oplus,wls_bpp_strategy =	<0 460 750 1000 1
						 440 530 400 1000 1>;

		/*
		 * | temp_min | temp_max | target_curr_ma | vol_max_mv | need_wait |
		 *
		 * temp_min: Switch to the previous level when the temperature is lower
		 *           than this value. If it is 0, do not switch.
		 * temp_max: Switch to the next level when the temperature is greater
		 *           than this value
		 * target_curr_ma: Target current in this temperature range.
		 * vol_max_mv: Maximum battery voltage.
		 * need_wait: 1:Need wait for a while after switching to the next level.
		 *            0:No need to wait after switching to the next level.
		 */
		non_ffc_strategy {
			wls_bpp_strategy {
				strategy_low_battery {
					wls_temp_little_cold = <(-100) 0 250 5000 0>;
					wls_temp_cool =	<0 50 450 5000 0>;
					wls_temp_little_cool = <50 120 750 5000 0>;
					wls_temp_pre_normal = <120 160 750 5000 0>;
					wls_temp_normal = <160 350 750 5000 0>;
					wls_temp_normal_high = <350 450 750 5000 0>;
					wls_temp_warm = <450 530 750 5000 0>;
				};
				strategy_high_battery {
					wls_temp_little_cold = <(-100) 0 250 5000 0>;
					wls_temp_cool =	<0 50 450 5000 0>;
					wls_temp_little_cool = <50 120 750 5000 0>;
					wls_temp_pre_normal = <120 160 750 5000 0>;
					wls_temp_normal = <160 350 750 5000 0>;
					wls_temp_normal_high = <350 450 750 5000 0>;
					wls_temp_warm = <450 530 750 5000 0>;
				};
			};

			wls_epp_strategy {
				strategy_low_battery {
					wls_temp_little_cold = <(-100) 0 250 5000 0>;
					wls_temp_cool =	<0 50 450 5000 0>;
					wls_temp_little_cool = <50 120 1450 4435 0
							50 120 1100 4455 0
							50 120 800 5000 0>;
					wls_temp_pre_normal = <120 160 1500 4435 0
							120 160 1100 4455 0
							120 160 800 5000 0>;
					wls_temp_normal = <160 350 1500 4435 0
							160 350 1100 4455 0
							160 350 800 5000 0>;
					wls_temp_normal_high = <350 450 1500 4415 0
							350 450 1100 4435 0
							350 450 800 5000 0>;
					wls_temp_warm = <450 530 800 5000 0>;
				};
				strategy_high_battery {
					wls_temp_little_cold = <(-100) 0 250 5000 0>;
					wls_temp_cool =	<0 50 450 5000 0>;
					wls_temp_little_cool = <50 120 800 5000 0>;
					wls_temp_pre_normal = <120 160 1450 4435 0
							120 160 1100 4455 0
							120 160 800 5000 0>;
					wls_temp_normal = <160 350 1500 4435 0
							160 350 1100 4455 0
							160 350 800 5000 0>;
					wls_temp_normal_high = <350 450 1500 4415 0
							350 450 1100 4435 0
							350 450 800 5000 0>;
					wls_temp_warm = <450 530 800 5000 0>;
				};
			};

			wls_epp_plus_strategy {
				strategy_low_battery {
					wls_temp_little_cold = <(-100) 0 250 5000 0>;
					wls_temp_cool =	<0 50 450 5000 0>;
					wls_temp_little_cool = <50 120 1450 4435 0
							50 120 1100 4455 0
							50 120 800 5000 0>;
					wls_temp_pre_normal = <120 160 1700 4430 0
							120 160 1500 4435 0
							120 160 1100 4455 0
							120 160 800 5000 0>;
					wls_temp_normal = <160 350 1700 4430 0
							160 350 1500 4435 0
							160 350 1100 4455 0
							160 350 800 5000 0>;
					wls_temp_normal_high = <350 450 1700 4410 0
							350 450 1500 4415 0
							350 450 1100 4435 0
							350 450 800 5000 0>;
					wls_temp_warm = <450 530 800 5000 0>;
				};
				strategy_high_battery {
					wls_temp_little_cold = <(-100) 0 250 5000 0>;
					wls_temp_cool =	<0 50 450 5000 0>;
					wls_temp_little_cool = <50 120 800 5000 0>;
					wls_temp_pre_normal = <120 160 1450 4435 0
							120 160 1100 4455 0
							120 160 800 5000 0>;
					wls_temp_normal = <160 350 1700 4430 0
							160 350 1500 4435 0
							160 350 1100 4455 0
							160 350 800 5000 0>;
					wls_temp_normal_high = <350 450 1700 4410 0
							350 450 1500 4415 0
							350 450 1100 4435 0
							350 450 800 5000 0>;
					wls_temp_warm = <450 530 400 5000 0>;
				};
			};

			wls_airvooc_strategy {
				strategy_low_battery {
					wls_temp_little_cold = <(-100) 0 250 5000 0>;
					wls_temp_cool =	<0 50 450 5000 0>;
					wls_temp_little_cool = <50 120 1300 4425 0
							50 120 750 5000 0>;
					wls_temp_pre_normal = <120 160 1800 4425 0
							120 160 750 5000 0>;
					wls_temp_normal = <160 350 1800 4425 0
							160 350 750 5000 0>;
					wls_temp_normal_high = 	<350 450 1800 4405 0
							350 450 750 5000 0>;
					wls_temp_warm = <450 530 750 5000 0>;
				};
				strategy_high_battery {
					wls_temp_little_cold = <(-100) 0 250 5000 0>;
					wls_temp_cool =	<0 50 450 5000 0>;
					wls_temp_little_cool = <50 120 750 5000 0>;
					wls_temp_pre_normal = <120 160 1300 4425 0
							120 160 750 5000 0>;
					wls_temp_normal = <160 350 1800 4425 0
							160 350 750 5000 0>;
					wls_temp_normal_high = 	<350 450 1800 4405 0
							350 450 750 5000 0>;
					wls_temp_warm = <450 530 750 5000 0>;
				};
			};

			wls_airsvooc_strategy {
				strategy_low_battery {
					wls_temp_little_cold = <(-100) 0 250 5000 0>;
					wls_temp_cool =	<0 50 450 5000 0>;
					wls_temp_little_cool = <50 120 1300 4425 0
							50 120 750 5000 0>;
					wls_temp_pre_normal = <120 160 1800 4425 0
							120 160 750 5000 0>;
					wls_temp_normal = <160 350 1800 4425 0
							160 350 750 5000 0>;
					wls_temp_normal_high = 	<350 450 1100 4435 0
							350 450 750 5000 0>;
					wls_temp_warm = <450 530 750 5000 0>;
				};
				strategy_high_battery {
					wls_temp_little_cold = <(-100) 0 250 5000 0>;
					wls_temp_cool =	<0 50 450 5000 0>;
					wls_temp_little_cool = <50 120 750 5000 0>;
					wls_temp_pre_normal = <120 160 1300 4425 0
							120 160 750 5000 0>;
					wls_temp_normal = <160 350 1800 4425 0
							160 350 750 5000 0>;
					wls_temp_normal_high = 	<350 450 1100 4435 0
							350 450 750 5000 0>;
					wls_temp_warm = <450 530 750 5000 0>;
				};
			};
		};

		/*
		 * | temp_min | temp_max | target_curr_ma | vol_max_mv | need_wait |
		 *
		 * temp_min: Switch to the previous level when the temperature is lower
		 *           than this value. If it is 0, do not switch.
		 * temp_max: Switch to the next level when the temperature is greater
		 *           than this value
		 * target_curr_ma: Target current in this temperature range.
		 * vol_max_mv: Maximum battery voltage.
		 * need_wait: 1:Need wait for a while after switching to the next level.
		 *            0:No need to wait after switching to the next level.
		 *            >1:Max running time(seconds) of this level
		 */
		wireless_fastchg_strategy {
			/* 0~20 */
			strategy_soc_0_to_30 {
				strategy_temp_0_to_50 =		<0 440 850 4070 1				//0~5
								 0 440 700 4080 0>;
				strategy_temp_50_to_120 =	<50 430 1500 4080 1				//5~12
								 50 440 1000 4080 1
								 50 440 800 4180 1
								 50 440 500 4570 0>;
				strategy_temp_120_to_160 = 	<120 361 3000 4080 1			//12~16
								 341 405 2500 4080 1
								 385 425 2000 4080 1
								 400 430 1500 4180 1
								 410 440 1000 4180 1
								 410 440 800 4560 1
								 410 440 600 4570 0>;
				strategy_temp_160_to_400 =      <120 343 3500 4080 1		//16~21
								 323 361 3000 4180 1
								 341 405 2500 4180 1
								 385 425 2000 4180 1
								 400 430 1500 4560 1
								 410 440 1000 4560 1
								 410 440 700 4570 0>;
				/* 21 ~ little warm */
				strategy_temp_160_to_400_high = <120 310 5000 4530 30		//21~35
								 160 343 3500 4560 1
								 323 361 3000 4560 1
								 341 371 2680 4560 1
								 385 425 2000 4560 1
								 400 430 1500 4560 1
								 410 440 1100 4570 0>;
				strategy_temp_400_to_440 =      <120 310 5000 4530 30		//35~44
								 160 343 3500 4540 1
								 323 361 3000 4540 1
								 341 405 2500 4540 1
								 385 425 2000 4540 1
								 400 430 1500 4540 1
								 410 440 1000 4540 0>;
			};

			/* 21~35 */
			strategy_soc_0_to_30_high {
				strategy_temp_0_to_50 =		<0 440 850 4070 1               //0~5
								 0 440 700 4080 0>;
				strategy_temp_50_to_120 =	<50 430 1500 4080 1             //5~12
								 50 440 1000 4080 1
								 50 440 800 4180 1
								 50 440 500 4570 0>;
				strategy_temp_120_to_160 = 	<120 361 3000 4080 1            //12~16
								 341 405 2500 4080 1
								 385 425 2000 4080 1
								 400 430 1500 4180 1
								 410 440 1000 4180 1
								 410 440 800 4560 1
								 410 440 600 4570 0>;
				strategy_temp_160_to_400 =      <120 343 3500 4080 1		//16~21
								 323 361 3000 4180 1
								 341 405 2500 4180 1
								 385 425 2000 4180 1
								 400 430 1500 4560 1
								 410 440 1000 4560 1
								 410 440 700 4570 0>;
				/* 21 ~ little warm */
				strategy_temp_160_to_400_high = <120 343 3500 4560 1		//21~35
								 323 361 3000 4560 1
								 341 405 2500 4560 1
								 385 425 2000 4560 1
								 400 430 1500 4560 1
								 410 440 1100 4570 0>;
				strategy_temp_400_to_440 =      <120 343 3500 4540 1		//35~44
								 323 361 3000 4540 1
								 341 405 2500 4540 1
								 385 425 2000 4540 1
								 400 430 1500 4540 1
								 410 440 1000 4540 0>;
			};

			/* 36~55 */
			strategy_soc_30_to_70 {
				strategy_temp_0_to_50 =		<0 440 850 4070 1               //0~5
								 0 440 700 4080 0>;
				strategy_temp_50_to_120 =	<50 430 1500 4080 1             //5~12
								 50 440 1000 4080 1
								 50 440 800 4180 1
								 50 440 500 4570 0>;
				strategy_temp_120_to_160 = 	<120 361 3000 4080 1            //12~16
								 341 405 2500 4080 1
								 385 425 2000 4080 1
								 400 430 1500 4180 1
								 410 440 1000 4180 1
								 410 440 800 4560 1
								 410 440 600 4570 0>;
				strategy_temp_160_to_400 =      <120 343 3500 4080 1		//16~21
								 323 361 3000 4180 1
								 341 405 2500 4180 1
								 385 425 2000 4180 1
								 400 430 1500 4560 1
								 410 440 1000 4560 1
								 410 440 700 4570 0>;
				/* 21 ~ little warm */
				strategy_temp_160_to_400_high = <120 343 3500 4560 1		//21~35
								 323 361 3000 4560 1
								 341 405 2500 4560 1
								 385 425 2000 4560 1
								 400 430 1500 4560 1
								 410 440 1100 4570 0>;
				strategy_temp_400_to_440 =      <120 343 3500 4540 1		//35~44
								 323 361 3000 4540 1
								 341 405 2500 4540 1
								 385 425 2000 4540 1
								 400 430 1500 4540 1
								 410 440 1000 4540 0>;
			};

			/* 56~75 */
			strategy_soc_30_to_70_high {
				strategy_temp_0_to_50 =		<0 440 850 4070 1               //0~5
								 0 440 700 4080 0>;
				strategy_temp_50_to_120 =	<50 430 1500 4080 1             //5~12
								 50 430 1000 4080 1
								 50 440 800 4180 1
								 50 440 500 4570 0>;
				strategy_temp_120_to_160 = 	<120 361 3000 4080 1            //12~16
								 341 405 2500 4080 1
								 385 425 2000 4080 1
								 400 430 1500 4180 1
								 410 440 1000 4180 1
								 410 440 800 4560 1
								 410 440 600 4570 0>;
				strategy_temp_160_to_400 =      <120 343 3500 4080 1		//16~21
								 323 361 3000 4180 1
								 341 405 2500 4180 1
								 385 425 2000 4180 1
								 400 430 1500 4560 1
								 410 440 1000 4560 1
								 410 440 700 4570 0>;
				/* 21 ~ little warm */
				strategy_temp_160_to_400_high = <120 343 3500 4560 1		//21~35
								 323 361 3000 4560 1
								 341 405 2500 4560 1
								 385 425 2000 4560 1
								 400 430 1500 4560 1
								 410 440 1100 4570 0>;
				strategy_temp_400_to_440 =      <120 343 3500 4540 1		//35~44
								 323 361 3000 4540 1
								 341 405 2500 4540 1
								 385 425 2000 4540 1
								 400 430 1500 4540 1
								 410 440 1000 4540 0>;
			};

			/* 76~85 */
			strategy_soc_70_to_90 {
				strategy_temp_0_to_50 =		<0 440 850 4070 1               //0~5
								 0 440 700 4080 0>;
				strategy_temp_50_to_120 =	<50 430 1500 4080 1             //5~12
								 50 440 1000 4080 1
								 50 440 800 4180 1
								 50 440 500 4570 0>;
				strategy_temp_120_to_160 = 	<120 361 3000 4080 1            //12~16
								 341 405 2500 4080 1
								 385 425 2000 4080 1
								 400 430 1500 4180 1
								 410 440 1000 4180 1
								 410 440 800 4560 1
								 410 440 600 4570 0>;
				strategy_temp_160_to_400 =      <120 361 3000 4180 1		//16~21
								 341 405 2500 4180 1
								 385 425 2000 4180 1
								 400 430 1500 4560 1
								 400 430 1000 4560 1
								 410 440 700 4570 0>;
				/* 21 ~ little warm */
				strategy_temp_160_to_400_high = <120 343 3500 4560 1		//21~35
								 323 361 3000 4560 1
								 341 405 2500 4560 1
								 385 425 2000 4560 1
								 400 430 1500 4560 1
								 410 440 1100 4570 0>;
				strategy_temp_400_to_440 =      <120 343 3500 4540 1		//35~44
								 323 361 3000 4540 1
								 341 405 2500 4540 1
								 385 425 2000 4540 1
								 400 430 1500 4540 1
								 410 440 1000 4540 0>;
			};

			/* 85~95 */
			strategy_soc_70_to_90_high {
				strategy_temp_0_to_50 =		<0 440 850 4070 1				//0~5
								 0 440 700 4080 0>;
				strategy_temp_50_to_120 =	<50 430 1500 4080 1				//5~12
								 50 440 1000 4080 1
								 50 440 800 4180 1
								 50 440 500 4570 0>;
				strategy_temp_120_to_160 =	<120 430 1500 4180 1			//12~16
								 410 440 1000 4180 1
								 410 440 800 4560 1
								 410 440 600 4570 0>;
				strategy_temp_160_to_400 =	<120 430 1500 4560 1			//16~21
								 410 440 1000 4560 1
								 410 440 700 4570 0>;
				strategy_temp_160_to_400_high =	<120 430 1500 4560 1		//21~35
								 410 440 1100 4570 0>;
				strategy_temp_400_to_440 =	<120 430 1500 4540 1			//35~44
								 410 440 1000 4540 0>;
			};
		};

		wireless_fastchg_strategy_magcvr {
			/* 0~20 */
			strategy_soc_0_to_30 {
				strategy_temp_0_to_50 =		<0 440 850 4070 1				//0~5
								 0 440 700 4080 0>;
				strategy_temp_50_to_120 =	<50 430 1500 4080 1				//5~12
								 50 440 1000 4080 1
								 50 440 800 4180 1
								 50 440 500 4570 0>;
				strategy_temp_120_to_160 = 	<120 365 3000 4080 1			//12~16
								 345 405 2500 4080 1
								 385 425 2000 4080 1
								 400 430 1500 4180 1
								 410 440 1000 4180 1
								 410 440 800 4560 1
								 410 440 600 4570 0>;
				strategy_temp_160_to_400 =      <120 343 3500 4080 1		//16~21
								 323 365 3000 4180 1
								 345 405 2500 4180 1
								 385 425 2000 4180 1
								 400 430 1500 4560 1
								 410 440 1000 4560 1
								 410 440 700 4570 0>;
				/* 21 ~ little warm */
				strategy_temp_160_to_400_high = <120 310 5000 4530 30		//21~35
								 160 343 3500 4560 1
								 323 365 3000 4560 1
								 345 385 2650 4560 1
								 385 425 2000 4560 1
								 400 430 1500 4560 1
								 410 440 1100 4570 0>;
				strategy_temp_400_to_440 =      <120 310 5000 4530 30		//35~44
								 160 343 3500 4540 1
								 323 365 3000 4540 1
								 345 405 2500 4540 1
								 385 425 2000 4540 1
								 400 430 1500 4540 1
								 410 440 1000 4540 0>;
			};

			/* 21~35 */
			strategy_soc_0_to_30_high {
				strategy_temp_0_to_50 =		<0 440 850 4070 1               //0~5
								 0 440 700 4080 0>;
				strategy_temp_50_to_120 =	<50 430 1500 4080 1             //5~12
								 50 440 1000 4080 1
								 50 440 800 4180 1
								 50 440 500 4570 0>;
				strategy_temp_120_to_160 = 	<120 365 3000 4080 1            //12~16
								 345 405 2500 4080 1
								 385 425 2000 4080 1
								 400 430 1500 4180 1
								 410 440 1000 4180 1
								 410 440 800 4560 1
								 410 440 600 4570 0>;
				strategy_temp_160_to_400 =      <120 343 3500 4080 1		//16~21
								 323 365 3000 4180 1
								 345 405 2500 4180 1
								 385 425 2000 4180 1
								 400 430 1500 4560 1
								 410 440 1000 4560 1
								 410 440 700 4570 0>;
				/* 21 ~ little warm */
				strategy_temp_160_to_400_high = <120 343 3500 4560 1		//21~35
								 323 365 3000 4560 1
								 345 405 2500 4560 1
								 385 425 2000 4560 1
								 400 430 1500 4560 1
								 410 440 1100 4570 0>;
				strategy_temp_400_to_440 =      <120 343 3500 4540 1		//35~44
								 323 365 3000 4540 1
								 345 405 2500 4540 1
								 385 425 2000 4540 1
								 400 430 1500 4540 1
								 410 440 1000 4540 0>;
			};

			/* 36~55 */
			strategy_soc_30_to_70 {
				strategy_temp_0_to_50 =		<0 440 850 4070 1               //0~5
								 0 440 700 4080 0>;
				strategy_temp_50_to_120 =	<50 430 1500 4080 1             //5~12
								 50 440 1000 4080 1
								 50 440 800 4180 1
								 50 440 500 4570 0>;
				strategy_temp_120_to_160 = 	<120 365 3000 4080 1            //12~16
								 345 405 2500 4080 1
								 385 425 2000 4080 1
								 400 430 1500 4180 1
								 410 440 1000 4180 1
								 410 440 800 4560 1
								 410 440 600 4570 0>;
				strategy_temp_160_to_400 =      <120 343 3500 4080 1		//16~21
								 323 365 3000 4180 1
								 345 405 2500 4180 1
								 385 425 2000 4180 1
								 400 430 1500 4560 1
								 410 440 1000 4560 1
								 410 440 700 4570 0>;
				/* 21 ~ little warm */
				strategy_temp_160_to_400_high = <120 343 3500 4560 1		//21~35
								 323 365 3000 4560 1
								 345 405 2500 4560 1
								 385 425 2000 4560 1
								 400 430 1500 4560 1
								 410 440 1100 4570 0>;
				strategy_temp_400_to_440 =      <120 343 3500 4540 1		//35~44
								 323 365 3000 4540 1
								 345 405 2500 4540 1
								 385 425 2000 4540 1
								 400 430 1500 4540 1
								 410 440 1000 4540 0>;
			};

			/* 56~75 */
			strategy_soc_30_to_70_high {
				strategy_temp_0_to_50 =		<0 440 850 4070 1               //0~5
								 0 440 700 4080 0>;
				strategy_temp_50_to_120 =	<50 430 1500 4080 1             //5~12
								 50 440 1000 4080 1
								 50 440 800 4180 1
								 50 440 500 4570 0>;
				strategy_temp_120_to_160 = 	<120 365 3000 4080 1            //12~16
								 345 405 2500 4080 1
								 385 425 2000 4080 1
								 400 430 1500 4180 1
								 410 440 1000 4180 1
								 410 440 800 4560 1
								 410 440 600 4570 0>;
				strategy_temp_160_to_400 =      <120 343 3500 4080 1		//16~21
								 323 365 3000 4180 1
								 345 405 2500 4180 1
								 385 425 2000 4180 1
								 400 430 1500 4560 1
								 410 440 1000 4560 1
								 410 440 700 4570 0>;
				/* 21 ~ little warm */
				strategy_temp_160_to_400_high = <120 343 3500 4560 1		//21~35
								 323 365 3000 4560 1
								 345 405 2500 4560 1
								 385 425 2000 4560 1
								 400 430 1500 4560 1
								 410 440 1100 4570 0>;
				strategy_temp_400_to_440 =      <120 343 3500 4540 1		//35~44
								 323 365 3000 4540 1
								 345 405 2500 4540 1
								 385 425 2000 4540 1
								 400 430 1500 4540 1
								 410 440 1000 4540 0>;
			};

			/* 76~85 */
			strategy_soc_70_to_90 {
				strategy_temp_0_to_50 =		<0 440 850 4070 1               //0~5
								 0 440 700 4080 0>;
				strategy_temp_50_to_120 =	<50 430 1500 4080 1             //5~12
								 50 440 1000 4080 1
								 50 440 800 4180 1
								 50 440 500 4570 0>;
				strategy_temp_120_to_160 = 	<120 365 3000 4080 1			//12~16
								 341 405 2500 4080 1
								 385 425 2000 4080 1
								 400 430 1500 4180 1
								 410 440 1000 4180 1
								 410 440 800 4560 1
								 410 440 600 4570 0>;
				strategy_temp_160_to_400 =      <120 365 3000 4180 1		//16~21
								 345 405 2500 4180 1
								 385 425 2000 4180 1
								 400 430 1500 4560 1
								 410 440 1000 4560 1
								 410 440 700 4570 0>;
				/* 21 ~ little warm */
				strategy_temp_160_to_400_high = <120 343 3500 4560 1		//21~35
								 323 365 3000 4560 1
								 345 405 2500 4560 1
								 385 425 2000 4560 1
								 400 430 1500 4560 1
								 410 440 1100 4570 0>;
				strategy_temp_400_to_440 =      <120 343 3500 4540 1		//35~44
								 323 365 3000 4540 1
								 345 405 2500 4540 1
								 385 425 2000 4540 1
								 400 430 1500 4540 1
								 410 440 1000 4540 0>;
			};

			/* 85~95 */
			strategy_soc_70_to_90_high {
				strategy_temp_0_to_50 =		<0 440 850 4070 1				//0~5
								 0 440 700 4080 0>;
				strategy_temp_50_to_120 =	<50 430 1500 4080 1				//5~12
								 50 440 1000 4080 1
								 50 440 800 4180 1
								 50 440 500 4570 0>;
				strategy_temp_120_to_160 =	<120 430 1500 4180 1			//12~16
								 410 440 1000 4180 1
								 410 440 800 4560 1
								 410 440 600 4570 0>;
				strategy_temp_160_to_400 =	<120 430 1500 4560 1			//16~21
								 410 440 1000 4560 1
								 410 440 700 4570 0>;
				strategy_temp_160_to_400_high =	<120 430 1500 4560 1		//21~35
								 410 440 1100 4570 0>;
				strategy_temp_400_to_440 =	<120 415 1500 4540 1			//35~44
								 410 440 1000 4540 0>;
			};
		};

		/*
		 * | max_batt_volt | max_current | min_current | end
		 *
		 * max_batt_volt: Maximum battery voltage.
		 * max_current: The maximum current in this interval.
		 * min_current: The result obtained by subtracting 1A from the
		 *				minimum current in this interval. Minimum not less than 1A.
		 * exit: Whether the curve ends or not.
		 */
		wireless_bcc_table {
			bcc_soc_0_to_30 {
				bcc_temp_0_to_50 =	<4070 1000 1000 0
							 4080 1000 1000 1>;
				bcc_temp_50_to_120 =	<4080 1500 1000 0
							 4180 1000 1000 0
							 4570 1000 1000 1>;
				bcc_temp_120_to_160 =	<4080 3000 1000 0
							 4180 1500 1000 0
							 4560 1000 1000 0
							 4570 1000 1000 1>;
				bcc_temp_160_to_400 =	<4080 3500 2500 0
							 4180 3000 1000 0
							 4560 1500 1000 0
							 4570 1000 1000 1>;
				bcc_temp_160_to_400_high =	<4530 5000 4000 0
							 4560 3500 1000 0
							 4570 1100 1000 1>;
				bcc_temp_400_to_440 =	<4530 5000 4000 0
							 4540 3500 1000 0
							 4540 1500 1000 0
							 4540 1000 1000 1>;
			};

			bcc_soc_0_to_30_high {
				bcc_temp_0_to_50 =	<4070 1000 1000 0
							 4080 1000 1000 1>;
				bcc_temp_50_to_120 =	<4080 1500 1000 0
							 4180 1000 1000 0
							 4570 1000 1000 1>;
				bcc_temp_120_to_160 =	<4080 3000 1000 0
							 4180 1500 1000 0
							 4560 1000 1000 0
							 4570 1000 1000 1>;
				bcc_temp_160_to_400 =	<4080 3500 2500 0
							 4180 3000 1000 0
							 4560 1500 1000 0
							 4570 1000 1000 1>;
				bcc_temp_160_to_400_high =	<4560 3500 1000 0
							 4570 1100 1000 1>;
				bcc_temp_400_to_440 =	<4540 3500 1000 0
							 4540 1500 1000 0
							 4540 1000 1000 1>;
			};

			bcc_soc_30_to_70 {
				bcc_temp_0_to_50 =	<4070 1000 1000 0
							 4080 1000 1000 1>;
				bcc_temp_50_to_120 =	<4080 1500 1000 0
							 4180 1000 1000 0
							 4570 1000 1000 1>;
				bcc_temp_120_to_160 =	<4080 3000 1000 0
							 4180 1500 1000 0
							 4560 1000 1000 0
							 4570 1000 1000 1>;
				bcc_temp_160_to_400 =	<4080 3500 1000 0
							 4180 3000 1000 0
							 4560 1500 1000 0
							 4570 1000 1000 1>;
				bcc_temp_160_to_400_high =	<4560 3500 1000 0
							 4570 1100 1000 1>;
				bcc_temp_400_to_440 =	<4540 3500 1000 0
							 4540 1500 1000 0
							 4540 1000 1000 1>;
			};

			bcc_soc_30_to_70_high {
				bcc_temp_0_to_50 =	<4070 1000 1000 0
							 4080 1000 1000 1>;
				bcc_temp_50_to_120 =	<4080 1500 1000 0
							 4180 1000 1000 0
							 4570 1000 1000 1>;
				bcc_temp_120_to_160 =	<4080 3000 1000 0
							 4180 1500 1000 0
							 4560 1000 1000 0
							 4570 1000 1000 1>;
				bcc_temp_160_to_400 =	<4080 3500 1000 0
							 4180 3000 1000 0
							 4560 1500 1000 0
							 4570 1000 1000 1>;
				bcc_temp_160_to_400_high =	<4560 3500 1000 0
							 4570 1100 1000 1>;
				bcc_temp_400_to_440 =	<4540 3500 1000 0
							 4540 1500 1000 0
							 4540 1000 1000 1>;
			};

			bcc_soc_70_to_90 {
				bcc_temp_0_to_50 =	<4070 1000 1000 0
							 4080 1000 1000 1>;
				bcc_temp_50_to_120 =	<4080 1500 1000 0
							 4180 1000 1000 0
							 4570 1000 1000 1>;
				bcc_temp_120_to_160 =	<4080 3000 1000 0
							 4180 1500 1000 0
							 4560 1000 1000 0
							 4570 1000 1000 1>;
				bcc_temp_160_to_400 =	<4180 3000 1000 0
							 4560 1500 1000 0
							 4570 1000 1000 1>;
				bcc_temp_160_to_400_high =	<4560 3500 1000 0
							 4570 1100 1000 1>;
				bcc_temp_400_to_440 =	<4540 3500 1000 0
							 4540 1500 1000 0
							 4540 1000 1000 1>;
			};

			bcc_soc_70_to_90_high {
				bcc_temp_0_to_50 =	<4070 1000 1000 0
							 4080 1000 1000 1>;
				bcc_temp_50_to_120 =	<4080 1500 1000 0
							 4180 1000 1000 0
							 4570 1000 1000 1>;
				bcc_temp_120_to_160 =	<4180 1500 1000 0
							 4560 1000 1000 0
							 4570 1000 1000 1>;
				bcc_temp_160_to_400 =	<4560 1500 1000 0
							 4570 1000 1000 1>;
				bcc_temp_160_to_400_high =	<4560 1500 1000 0
							 4570 1100 1000 1>;
				bcc_temp_400_to_440 =	<4540 1500 1000 0
							 4540 1000 1000 1>;
			};
		};
	};
};

&soc {
	oplus_virtual_rx: oplus,virtual_rx {
		compatible = "oplus,virtual_rx";
		oplus,rx_ic = <&oplus_rx_sc96257>;
		oplus,rx_ic_index = <0>;
		oplus,rx_ic_func_group = <&sc96257_rx_groups>;
		oplus,ic_type = <OPLUS_CHG_IC_VIRTUAL_RX>;
		oplus,ic_index = <0>;
	};
	oplus_virtual_cp: oplus,virtual_cp {
		compatible = "oplus,virtual_cp";
		oplus,cp_ic = <&oplus_cp_sc96257>;
		oplus,cp_ic_connect = <OPLUS_CHG_IC_CONNECT_PARALLEL>;
		oplus,main_cp = <0>;
		oplus,input_curr_max_ma = <5000>;
		oplus,ic_func_group = <&sc96257_cp_groups>;
		oplus,ic_type = <OPLUS_CHG_IC_VIRTUAL_CP>;
		oplus,ic_index = <0>;
	};
};

&tlmm {
	rx_event_default: rx_event_default {
		mux {
			pins = "gpio169";
			function = "gpio";
		};
		config {
			pins = "gpio169";
			drive-strength = <2>;
			input-enable;
			bias-disable;
		};
	};

	rx_con_default: rx_con_default {
		mux {
			pins = "gpio57";
			function = "gpio";
		};
		config {
			pins = "gpio57";
			drive-strength = <2>;
			bias-disable;
			input-enable;
		};
	};
};

&pmih010x_gpios {
	rx_en_sleep: rx_en_sleep {
		pins = "gpio2";
		function = "normal";
		input-disable;
		bias-disable;
		power-source = <2>;
		output-high;
		qcom,drive-strength = <3>;
	};

	rx_en_active: rx_en_active {
		pins = "gpio2";
		function = "normal";
		input-disable;
		bias-disable;
		power-source = <2>;
		output-low;
		qcom,drive-strength = <3>;
	};

	insert_dis_active: insert_dis_active {
		pins = "gpio8";
		function = "normal";
		input-disable;
		bias-disable;
		power-source = <2>;
		output-high;
		qcom,drive-strength = <3>;
	};
	insert_dis_sleep: insert_dis_sleep {
		pins = "gpio8";
		function = "normal";
		input-disable;
		bias-disable;
		power-source = <2>;
		output-low;
		qcom,drive-strength = <3>;
	};
};

&qupv3_hub_i2c1_sda_active {
	config {
		qcom,i2c_pull;
	};
};
&qupv3_hub_i2c1_scl_active {
	config {
		qcom,i2c_pull;
	};
};

&qupv3_hub_i2c1 {
	status = "ok";
	qcom,clk-freq-out = <400000>;

	oplus_sc96257: oplus,sc96257@37 {
		status = "ok";
		compatible = "oplus,rx-sc96257";
		reg = <0x37>;
		#address-cells = <1>;
		#size-cells = <0>;
		oplus,nor_ic = <&oplus_virtual_buck>;
		oplus,support_epp_11w;

		oplus,rx_event-gpio = <&tlmm 169 0x00>;//check
		oplus,rx_con-gpio = <&tlmm 57 0x00>;//check
		oplus,rx_en-gpio = <&pmih010x_gpios 2 0x00>;//vt-sleep check
		oplus,insert_dis-gpio = <&pmih010x_gpios 8 0x00>;//wls force pd check
		pinctrl-names = "rx_event_default", "rx_con_default",
				"rx_en_sleep", "rx_en_active",
				"insert_dis_active", "insert_dis_sleep";
		pinctrl-0 = <&rx_event_default>;
		pinctrl-1 = <&rx_con_default>;
		pinctrl-2 = <&rx_en_sleep>;
		pinctrl-3 = <&rx_en_active>;
		pinctrl-4 = <&insert_dis_active>;
		pinctrl-5 = <&insert_dis_sleep>;

		oplus_rx_sc96257: oplus,rx_sc96257 {
			oplus,ic_type = <OPLUS_CHG_IC_RX>;
			oplus,ic_index = <0>;
		};

		oplus_cp_sc96257: oplus,cp_sc96257 {
			oplus,ic_type = <OPLUS_CHG_IC_CP>;
			oplus,ic_index = <0>;
		};
	};
};
//#endif OPLUS_FEATURE_CHG_BASIC /*for wls charging config*/

&soc {
	oplus_chg_plc: oplus,plc_charge {
		compatible = "oplus,plc_charge";
		oplus,plc_soc = <90>;
		oplus,plc_support_timeout;
		oplus,plc_strategy-data = <&buck_simple_strategy>;
		oplus,plc_strategy-names = "default";

		oplus_ufcs_step_strategy: oplus_ufcs_step_strategy {
			oplus,strategy_type = <PLC_STRATEGY_STEP>;
		};

		cp_2t1_simple_strategy: cp_2t1_simple_strategy {
			oplus,strategy_type = <PLC_STRATEGY_SIMPLE>;
			oplus,strategy_data {
				strategy_curr_ma = <1000 1500>;
			};
		};

		cp_1t1_simple_strategy: cp_1t1_simple_strategy {
			oplus,strategy_type = <PLC_STRATEGY_SIMPLE>;
			oplus,strategy_data {
				strategy_curr_ma = <2000 3000>;
			};
		};

		buck_simple_strategy: buck_simple_strategy {
			oplus,strategy_type = <PLC_STRATEGY_SIMPLE>;
		};
	};
};

#include "oplus-chg-24624-silicon-p-dodge.dtsi"
